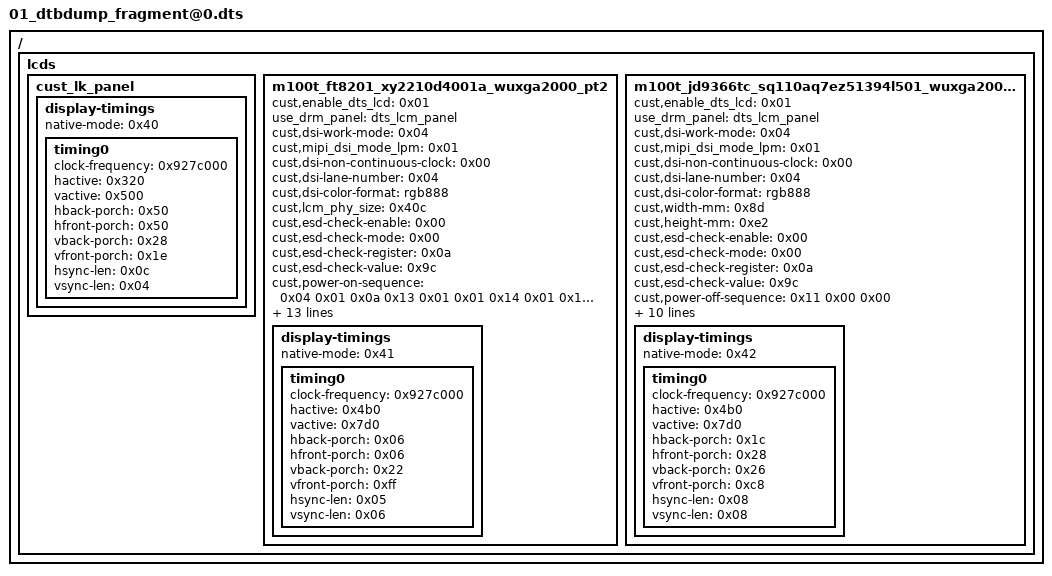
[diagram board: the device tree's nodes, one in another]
/dts-v1/;

/ {

	fragment@0 {
		target = <0xffffffff>;

		__overlay__ {

			cam0@0 {
				phandle = <0x02>;

				pins_cmd_dat {
					pinmux = <0x1400>;
					slew-rate = <0x01>;
					output-low;
				};
			};

			cam0@1 {
				phandle = <0x03>;

				pins_cmd_dat {
					pinmux = <0x1400>;
					slew-rate = <0x01>;
					output-high;
				};
			};

			cam0@2 {
				phandle = <0x17>;

				pins_cmd_dat {
					pinmux = <0x1300>;
					slew-rate = <0x01>;
					output-low;
				};
			};

			cam0@3 {
				phandle = <0x18>;

				pins_cmd_dat {
					pinmux = <0x1300>;
					slew-rate = <0x01>;
					output-high;
				};
			};

			cam1@0 {
				phandle = <0x04>;

				pins_cmd_dat {
					pinmux = <0x1000>;
					slew-rate = <0x01>;
					output-low;
				};
			};

			cam1@1 {
				phandle = <0x05>;

				pins_cmd_dat {
					pinmux = <0x1000>;
					slew-rate = <0x01>;
					output-high;
				};
			};

			cam1@2 {
				phandle = <0x19>;

				pins_cmd_dat {
					pinmux = <0x1100>;
					slew-rate = <0x01>;
					output-low;
				};
			};

			cam1@3 {
				phandle = <0x1a>;

				pins_cmd_dat {
					pinmux = <0x1100>;
					slew-rate = <0x01>;
					output-high;
				};
			};

			cam2@0 {
				phandle = <0x06>;

				pins_cmd_dat {
					pinmux = <0x1600>;
					slew-rate = <0x01>;
					output-low;
				};
			};

			cam2@1 {
				phandle = <0x07>;

				pins_cmd_dat {
					pinmux = <0x1600>;
					slew-rate = <0x01>;
					output-high;
				};
			};

			cam2@2 {
				phandle = <0x2b>;

				pins_cmd_dat {
					pinmux = <0x1500>;
					slew-rate = <0x01>;
					output-low;
				};
			};

			cam2@3 {
				phandle = <0x2c>;

				pins_cmd_dat {
					pinmux = <0x1500>;
					slew-rate = <0x01>;
					output-high;
				};
			};

			camera_pins_cam0_mclk_off {
				phandle = <0x08>;

				pins_cmd_dat {
					pinmux = <0x8000>;
					drive-strength = <0x01>;
				};
			};

			camera_pins_cam0_mclk_2ma {
				phandle = <0x09>;

				pins_cmd_dat {
					pinmux = <0x8001>;
					drive-strength = <0x00>;
				};
			};

			camera_pins_cam0_mclk_4ma {
				phandle = <0x0a>;

				pins_cmd_dat {
					pinmux = <0x8001>;
					drive-strength = <0x01>;
				};
			};

			camera_pins_cam0_mclk_6ma {
				phandle = <0x0b>;

				pins_cmd_dat {
					pinmux = <0x8001>;
					drive-strength = <0x02>;
				};
			};

			camera_pins_cam0_mclk_8ma {
				phandle = <0x0c>;

				pins_cmd_dat {
					pinmux = <0x8001>;
					drive-strength = <0x03>;
				};
			};

			camera_pins_cam1_mclk_off {
				phandle = <0x0d>;

				pins_cmd_dat {
					pinmux = <0x7e00>;
					drive-strength = <0x01>;
				};
			};

			camera_pins_cam1_mclk_2ma {
				phandle = <0x0e>;

				pins_cmd_dat {
					pinmux = <0x7e01>;
					drive-strength = <0x00>;
				};
			};

			camera_pins_cam1_mclk_4ma {
				phandle = <0x0f>;

				pins_cmd_dat {
					pinmux = <0x7e01>;
					drive-strength = <0x01>;
				};
			};

			camera_pins_cam1_mclk_6ma {
				phandle = <0x10>;

				pins_cmd_dat {
					pinmux = <0x7e01>;
					drive-strength = <0x02>;
				};
			};

			camera_pins_cam1_mclk_8ma {
				phandle = <0x11>;

				pins_cmd_dat {
					pinmux = <0x7e01>;
					drive-strength = <0x03>;
				};
			};

			camera_pins_cam2_mclk_off {
				phandle = <0x12>;

				pins_cmd_dat {
					pinmux = <0x8100>;
					drive-strength = <0x01>;
				};
			};

			camera_pins_cam2_mclk_2ma {
				phandle = <0x13>;

				pins_cmd_dat {
					pinmux = <0x8101>;
					drive-strength = <0x00>;
				};
			};

			camera_pins_cam2_mclk_4ma {
				phandle = <0x14>;

				pins_cmd_dat {
					pinmux = <0x8101>;
					drive-strength = <0x01>;
				};
			};

			camera_pins_cam2_mclk_6ma {
				phandle = <0x15>;

				pins_cmd_dat {
					pinmux = <0x8101>;
					drive-strength = <0x02>;
				};
			};

			camera_pins_cam2_mclk_8ma {
				phandle = <0x16>;

				pins_cmd_dat {
					pinmux = <0x8101>;
					drive-strength = <0x03>;
				};
			};

			camdefault {
				phandle = <0x01>;
			};

			vcama@0 {
				phandle = <0x1b>;

				pins_cmd_dat {
					pinmux = <0x9d00>;
					slew-rate = <0x01>;
					output-low;
				};
			};

			vcama@1 {
				phandle = <0x1c>;

				pins_cmd_dat {
					pinmux = <0x9d00>;
					slew-rate = <0x01>;
					output-high;
				};
			};

			vcamio@0 {
				phandle = <0x1d>;

				pins_cmd_dat {
					pinmux = <0x9f00>;
					slew-rate = <0x01>;
					output-low;
				};
			};

			vcamio@1 {
				phandle = <0x1e>;

				pins_cmd_dat {
					pinmux = <0x9f00>;
					slew-rate = <0x01>;
					output-high;
				};
			};

			vcamd@0 {
				phandle = <0x1f>;

				pins_cmd_dat {
					pinmux = <0x9e00>;
					slew-rate = <0x01>;
					output-low;
				};
			};

			vcamd@1 {
				phandle = <0x20>;

				pins_cmd_dat {
					pinmux = <0x9e00>;
					slew-rate = <0x01>;
					output-high;
				};
			};

			vcamaf@0 {
				phandle = <0x21>;

				pins_cmd_dat {
					pinmux = <0x9c00>;
					slew-rate = <0x01>;
					output-low;
				};
			};

			vcamaf@1 {
				phandle = <0x22>;

				pins_cmd_dat {
					pinmux = <0x9c00>;
					slew-rate = <0x01>;
					output-high;
				};
			};

			vcama_1@0 {
				phandle = <0x23>;

				pins_cmd_dat {
					pinmux = <0x9d00>;
					slew-rate = <0x01>;
					output-low;
				};
			};

			vcama_1@1 {
				phandle = <0x24>;

				pins_cmd_dat {
					pinmux = <0x9d00>;
					slew-rate = <0x01>;
					output-high;
				};
			};

			vcamio_1@0 {
				phandle = <0x25>;

				pins_cmd_dat {
					pinmux = <0x9f00>;
					slew-rate = <0x01>;
					output-low;
				};
			};

			vcamio_1@1 {
				phandle = <0x26>;

				pins_cmd_dat {
					pinmux = <0x9f00>;
					slew-rate = <0x01>;
					output-high;
				};
			};

			vcamd_1@0 {
				phandle = <0x27>;

				pins_cmd_dat {
					pinmux = <0x9e00>;
					slew-rate = <0x01>;
					output-low;
				};
			};

			vcamd_1@1 {
				phandle = <0x28>;

				pins_cmd_dat {
					pinmux = <0x9e00>;
					slew-rate = <0x01>;
					output-high;
				};
			};

			vcamaf_1@0 {
				phandle = <0x29>;

				pins_cmd_dat {
					pinmux = <0x9c00>;
					slew-rate = <0x01>;
					output-low;
				};
			};

			vcamaf_1@1 {
				phandle = <0x2a>;

				pins_cmd_dat {
					pinmux = <0x9c00>;
					slew-rate = <0x01>;
					output-high;
				};
			};

			vcama_2@0 {
				phandle = <0x2d>;

				pins_cmd_dat {
					pinmux = <0x9600>;
					slew-rate = <0x01>;
					output-low;
				};
			};

			vcama_2@1 {
				phandle = <0x2e>;

				pins_cmd_dat {
					pinmux = <0x9600>;
					slew-rate = <0x01>;
					output-high;
				};
			};

			vcamio_2@0 {
				phandle = <0x2f>;

				pins_cmd_dat {
					pinmux = <0x9f00>;
					slew-rate = <0x01>;
					output-low;
				};
			};

			vcamio_2@1 {
				phandle = <0x30>;

				pins_cmd_dat {
					pinmux = <0x9f00>;
					slew-rate = <0x01>;
					output-high;
				};
			};

			vcamd_2@0 {
				phandle = <0x31>;

				pins_cmd_dat {
					pinmux = <0x9700>;
					slew-rate = <0x01>;
					output-low;
				};
			};

			vcamd_2@1 {
				phandle = <0x32>;

				pins_cmd_dat {
					pinmux = <0x9700>;
					slew-rate = <0x01>;
					output-high;
				};
			};

			vcamaf_2@0 {
				phandle = <0x33>;

				pins_cmd_dat {
					pinmux = <0x9900>;
					slew-rate = <0x01>;
					output-low;
				};
			};

			vcamaf_2@1 {
				phandle = <0x34>;

				pins_cmd_dat {
					pinmux = <0x9900>;
					slew-rate = <0x01>;
					output-high;
				};
			};
		};
	};

	fragment@1 {
		target = <0xffffffff>;

		__overlay__ {
			pinctrl-names = "default\0cam0_rst0\0cam0_rst1\0cam1_rst0\0cam1_rst1\0cam2_rst0\0cam2_rst1\0cam0_mclk_off\0cam0_mclk_2mA\0cam0_mclk_4mA\0cam0_mclk_6mA\0cam0_mclk_8mA\0cam1_mclk_off\0cam1_mclk_2mA\0cam1_mclk_4mA\0cam1_mclk_6mA\0cam1_mclk_8mA\0cam2_mclk_off\0cam2_mclk_2mA\0cam2_mclk_4mA\0cam2_mclk_6mA\0cam2_mclk_8mA\0cam0_pnd0\0cam0_pnd1\0cam1_pnd0\0cam1_pnd1\0cam0_ldo_vcama_0\0cam0_ldo_vcama_1\0cam0_ldo_vcamio_0\0cam0_ldo_vcamio_1\0cam0_ldo_vcamd_0\0cam0_ldo_vcamd_1\0cam0_ldo_vcamafvdd_0\0cam0_ldo_vcamafvdd_1\0cam1_ldo_vcama_0\0cam1_ldo_vcama_1\0cam1_ldo_vcamio_0\0cam1_ldo_vcamio_1\0cam1_ldo_vcamd_0\0cam1_ldo_vcamd_1\0cam1_ldo_vcamafvdd_0\0cam1_ldo_vcamafvdd_1\0cam2_pnd0\0cam2_pnd1\0cam2_ldo_vcama_0\0cam2_ldo_vcama_1\0cam2_ldo_vcamio_0\0cam2_ldo_vcamio_1\0cam2_ldo_vcamd_0\0cam2_ldo_vcamd_1\0cam2_ldo_vcamafvdd_0\0cam2_ldo_vcamafvdd_1";
			pinctrl-0 = <0x01>;
			pinctrl-1 = <0x02>;
			pinctrl-2 = <0x03>;
			pinctrl-3 = <0x04>;
			pinctrl-4 = <0x05>;
			pinctrl-5 = <0x06>;
			pinctrl-6 = <0x07>;
			pinctrl-7 = <0x08>;
			pinctrl-8 = <0x09>;
			pinctrl-9 = <0x0a>;
			pinctrl-10 = <0x0b>;
			pinctrl-11 = <0x0c>;
			pinctrl-12 = <0x0d>;
			pinctrl-13 = <0x0e>;
			pinctrl-14 = <0x0f>;
			pinctrl-15 = <0x10>;
			pinctrl-16 = <0x11>;
			pinctrl-17 = <0x12>;
			pinctrl-18 = <0x13>;
			pinctrl-19 = <0x14>;
			pinctrl-20 = <0x15>;
			pinctrl-21 = <0x16>;
			pinctrl-22 = <0x17>;
			pinctrl-23 = <0x18>;
			pinctrl-24 = <0x19>;
			pinctrl-25 = <0x1a>;
			pinctrl-26 = <0x1b>;
			pinctrl-27 = <0x1c>;
			pinctrl-28 = <0x1d>;
			pinctrl-29 = <0x1e>;
			pinctrl-30 = <0x1f>;
			pinctrl-31 = <0x20>;
			pinctrl-32 = <0x21>;
			pinctrl-33 = <0x22>;
			pinctrl-34 = <0x23>;
			pinctrl-35 = <0x24>;
			pinctrl-36 = <0x25>;
			pinctrl-37 = <0x26>;
			pinctrl-38 = <0x27>;
			pinctrl-39 = <0x28>;
			pinctrl-40 = <0x29>;
			pinctrl-41 = <0x2a>;
			pinctrl-42 = <0x2b>;
			pinctrl-43 = <0x2c>;
			pinctrl-44 = <0x2d>;
			pinctrl-45 = <0x2e>;
			pinctrl-46 = <0x2f>;
			pinctrl-47 = <0x30>;
			pinctrl-48 = <0x31>;
			pinctrl-49 = <0x32>;
			pinctrl-50 = <0x33>;
			pinctrl-51 = <0x34>;
			cam0_pin_mclk = "mclk";
			cam0_pin_pdn = "gpio";
			cam0_pin_rst = "gpio";
			cam0_pin_vcama = "gpio";
			cam0_pin_vcamio = "gpio";
			cam0_pin_vcamd = "gpio";
			cam0_pin_vcama1 = "gpio";
			cam0_pin_vcamaf = "gpio";
			cam1_pin_mclk = "mclk";
			cam1_pin_pdn = "gpio";
			cam1_pin_rst = "gpio";
			cam1_pin_vcama = "gpio";
			cam1_pin_vcamio = "gpio";
			cam1_pin_vcamd = "gpio";
			cam1_pin_vcama1 = "gpio";
			cam1_pin_vcamaf = "gpio";
			cam2_pin_mclk = "mclk";
			cam2_pin_pdn = "gpio";
			cam2_pin_rst = "gpio";
			cam2_pin_vcama = "gpio";
			cam2_pin_vcamio = "gpio";
			cam2_pin_vcamd = "gpio";
			cam2_pin_vcama1 = "gpio";
			cam2_pin_vcamaf = "gpio";
			status = "okay";
		};
	};

	fragment@2 {
		target = <0xffffffff>;

		__overlay__ {
			status = "okay";
			clock-frequency = <0x61a80>;
			#address-cells = <0x01>;
			#size-cells = <0x00>;

			camera_eeprom2@51 {
				compatible = "mediatek,camera_eeprom";
				reg = <0x51>;
				status = "okay";
				phandle = <0x60>;
			};

			camera_main_two@10 {
				compatible = "mediatek,camera_main_two";
				#thermal-sensor-cells = <0x00>;
				reg = <0x10>;
				status = "okay";
				phandle = <0x37>;
			};

			camera_main_two_af@0d {
				compatible = "mediatek,camera_main_two_af";
				reg = <0x0d>;
				status = "okay";
				phandle = <0x61>;
			};

			camera_main_three_af@0c {
				compatible = "mediatek,camera_main_three_af";
				reg = <0x0c>;
				status = "okay";
				phandle = <0x62>;
			};
		};
	};

	fragment@3 {
		target = <0xffffffff>;

		__overlay__ {
			status = "okay";
			clock-frequency = <0x61a80>;
			#address-cells = <0x01>;
			#size-cells = <0x00>;

			camera_eeprom1@51 {
				compatible = "mediatek,camera_eeprom";
				reg = <0x51>;
				status = "okay";
				phandle = <0x63>;
			};

			camera_sub@1a {
				compatible = "mediatek,camera_sub";
				#thermal-sensor-cells = <0x00>;
				reg = <0x1a>;
				status = "okay";
				phandle = <0x36>;
			};
		};
	};

	fragment@4 {
		target = <0xffffffff>;

		__overlay__ {
			status = "okay";
			clock-frequency = <0x61a80>;
			#address-cells = <0x01>;
			#size-cells = <0x00>;

			camera_eeprom0@50 {
				compatible = "mediatek,camera_eeprom";
				reg = <0x50>;
				status = "okay";
				phandle = <0x64>;
			};

			camera_main@1a {
				compatible = "mediatek,camera_main";
				#thermal-sensor-cells = <0x00>;
				reg = <0x1a>;
				status = "okay";
				phandle = <0x35>;
			};

			camera_main_af@72 {
				compatible = "mediatek,camera_main_af";
				reg = <0x72>;
				status = "okay";
				phandle = <0x65>;
			};
		};
	};

	fragment@5 {
		target = <0xffffffff>;

		__overlay__ {

			camera_main {
				polling-delay = <0x3e8>;
				polling-delay-passive = <0x00>;
				thermal-sensors = <0x35>;
				phandle = <0x66>;
			};

			camera_sub {
				polling-delay = <0x3e8>;
				polling-delay-passive = <0x00>;
				thermal-sensors = <0x36>;
				phandle = <0x67>;
			};

			camera_main_two {
				polling-delay = <0x3e8>;
				polling-delay-passive = <0x00>;
				thermal-sensors = <0x37>;
				phandle = <0x68>;
			};
		};
	};

	fragment@6 {
		target = <0xffffffff>;

		__overlay__ {

			lm3643@63 {
				compatible = "mediatek,lm3643";
				reg = <0x63>;
				#cooling-cells = <0x02>;
				status = "okay";
				phandle = <0x69>;

				flash@0 {
					reg = <0x00>;
					type = <0x00>;
					ct = <0x00>;
					part = <0x00>;

					port@0 {

						endpoint {
							remote-endpoint = <0x38>;
							phandle = <0x3a>;
						};
					};
				};

				flash@1 {
					reg = <0x01>;
					type = <0x00>;
					ct = <0x01>;
					part = <0x00>;

					port@1 {

						endpoint {
							remote-endpoint = <0x39>;
							phandle = <0x3b>;
						};
					};
				};
			};
		};
	};

	fragment@7 {
		target = <0xffffffff>;

		__overlay__ {

			port@0 {

				endpoint {
					remote-endpoint = <0x3a>;
					phandle = <0x38>;
				};
			};

			port@1 {

				endpoint {
					remote-endpoint = <0x3b>;
					phandle = <0x39>;
				};
			};
		};
	};

	fragment@8 {
		target = <0xffffffff>;

		__overlay__ {
			camaf_m1_pmic-supply = <0xffffffff>;
			camaf_m2_pmic-supply = <0xffffffff>;
			camaf_m3_pmic-supply = <0xffffffff>;
			status = "okay";
		};
	};

	fragment@9 {
		target = <0xffffffff>;

		__overlay__ {

			hwen_high {
				phandle = <0x3c>;

				pins_cmd_dat {
					pinmux = <0x9a00>;
					slew-rate = <0x01>;
					output-high;
				};
			};

			hwen_low {
				phandle = <0x3d>;

				pins_cmd_dat {
					pinmux = <0x9a00>;
					slew-rate = <0x01>;
					output-low;
				};
			};

			mode_high {
				phandle = <0x3e>;

				pins_cmd_dat {
					pinmux = <0x9b00>;
					slew-rate = <0x01>;
					output-high;
				};
			};

			mode_low {
				phandle = <0x3f>;

				pins_cmd_dat {
					pinmux = <0x9b00>;
					slew-rate = <0x01>;
					output-low;
				};
			};
		};
	};

	fragment@10 {
		target = <0xffffffff>;

		__overlay__ {
			pinctrl-names = "hwen_high\0hwen_low\0mode_high\0mode_low";
			pinctrl-0 = <0x3c>;
			pinctrl-1 = <0x3d>;
			pinctrl-2 = <0x3e>;
			pinctrl-3 = <0x3f>;
			status = "okay";
		};
	};

	fragment@11 {
		target = <0xffffffff>;

		__overlay__ {
			DIFFERENCE_FULLOCV_ITH = <0xc8>;
			SHUTDOWN_1_TIME = <0x05>;
			KEEP_100_PERCENT = <0x01>;
			R_FG_VALUE = <0x05>;
			EMBEDDED_SEL = <0x01>;
			PMIC_SHUTDOWN_CURRENT = <0x14>;
			FG_METER_RESISTANCE = <0x46>;
			CAR_TUNE_VALUE = <0x64>;
			PMIC_MIN_VOL = <0x82dc>;
			POWERON_SYSTEM_IBOOT = <0x1f4>;
			SHUTDOWN_GAUGE0_VOLTAGE = <0x84d0>;
			TEMPERATURE_T0 = <0x32>;
			TEMPERATURE_T1 = <0x19>;
			TEMPERATURE_T2 = <0x0a>;
			TEMPERATURE_T3 = <0x00>;
			TEMPERATURE_T4 = <0xfffffff9>;
			TEMPERATURE_T5 = <0xfffffff6>;
			g_FG_PSEUDO100_T0 = <0x62>;
			g_FG_PSEUDO100_T1 = <0x62>;
			g_FG_PSEUDO100_T2 = <0x62>;
			g_FG_PSEUDO100_T3 = <0x62>;
			g_FG_PSEUDO100_T4 = <0x62>;
			Q_MAX_SYS_VOLTAGE_BAT0 = <0xd48>;
			Q_MAX_SYS_VOLTAGE_BAT1 = <0xd48>;
			Q_MAX_SYS_VOLTAGE_BAT2 = <0xd48>;
			Q_MAX_SYS_VOLTAGE_BAT3 = <0xd48>;
			COM_FG_METER_RESISTANCE = <0x64>;
			COM_R_FG_VALUE = <0x00>;
			enable_tmp_intr_suspend = <0x00>;
			ACTIVE_TABLE = <0x06>;
			MULTI_TEMP_GAUGE0 = <0x01>;
			RBAT_PULL_UP_VOLT = <0xaf0>;
			g_SHUTDOWN_HL_ZCV = <0xd48 0xd48 0xd48 0xd48 0xd48 0xd48 0xd48 0xd48 0xd48 0xd48 0xd48 0xd48 0xd48 0xd48 0xd48 0xd48 0xd48 0xd48 0xd48 0xd48>;
			UI_LOW_LIMIT_EN = <0x01>;
			UI_LOW_LIMIT_SOC0 = <0x64>;
			UI_LOW_LIMIT_VTH0 = <0x86c4>;
			UI_LOW_LIMIT_SOC1 = <0x64>;
			UI_LOW_LIMIT_VTH1 = <0x86c4>;
			UI_LOW_LIMIT_SOC2 = <0x64>;
			UI_LOW_LIMIT_VTH2 = <0x86c4>;
			UI_LOW_LIMIT_SOC3 = <0xc8>;
			UI_LOW_LIMIT_VTH3 = <0x8854>;
			UI_LOW_LIMIT_SOC4 = <0xc8>;
			UI_LOW_LIMIT_VTH4 = <0x8854>;
			VBAT2_DET_VOLTAGE1 = <0x84d0>;
			VBAT2_DET_VOLTAGE2 = <0x82dc>;
			VBAT2_DET_VOLTAGE3 = <0x80e8>;
			battery0_profile_t0_num = <0x64>;
			battery0_profile_t0_col = <0x03>;
			battery0_profile_t0 = <0x00 0xa97e 0x384 0x708 0xa776 0x384 0xa8c 0xa6fe 0x384 0xe10 0xa69a 0x384 0x1194 0xa62c 0x384 0x1518 0xa5c8 0x384 0x189c 0xa55a 0x37a 0x1c20 0xa50a 0x384 0x1fa4 0xa49c 0x384 0x26ac 0xa3e8 0x384 0x2a30 0xa384 0x384 0x2db4 0xa320 0x384 0x3138 0xa2c6 0x384 0x34bc 0xa24e 0x370 0x3840 0xa208 0x384 0x3bc4 0xa1ae 0x384 0x3f48 0xa14a 0x384 0x4650 0xa096 0x384 0x49d4 0xa03c 0x384 0x4d58 0x9fe2 0x384 0x50dc 0x9f88 0x384 0x5460 0x9f2e 0x384 0x57e4 0x9ed4 0x384 0x5b68 0x9e7a 0x384 0x5eec 0x9e2a 0x384 0x6270 0x9dda 0x384 0x6978 0x9d30 0x37a 0x6cfc 0x9cd6 0x370 0x7080 0x9c7c 0x37a 0x7404 0x9c18 0x384 0x7788 0x9ba0 0x370 0x7b0c 0x9b50 0x370 0x7e90 0x9b00 0x370 0x8214 0x9aba 0x370 0x891c 0x9a42 0x37a 0x8ca0 0x99f2 0x370 0x9024 0x99b6 0x37a 0x93a8 0x9966 0x370 0x972c 0x992a 0x37a 0x9ab0 0x98d0 0x370 0x9e34 0x9894 0x384 0xa1b8 0x984e 0x384 0xa8c0 0x97ae 0x37a 0xac44 0x9768 0x384 0xafc8 0x9722 0x384 0xb34c 0x96e6 0x384 0xb6d0 0x9696 0x370 0xba54 0x966e 0x384 0xbdd8 0x9632 0x384 0xc15c 0x9600 0x37a 0xc4e0 0x95ce 0x37a 0xcbe8 0x9574 0x384 0xcf6c 0x954c 0x384 0xd2f0 0x951a 0x37a 0xd674 0x94f2 0x384 0xd9f8 0x94ca 0x37a 0xdd7c 0x94ac 0x384 0xe100 0x9484 0x384 0xe484 0x945c 0x37a 0xeb8c 0x9416 0x37a 0xef10 0x93f8 0x384 0xf294 0x93c6 0x370 0xf618 0x93b2 0x37a 0xf99c 0x939e 0x384 0xfd20 0x9380 0x384 0x100a4 0x934e 0x370 0x10428 0x9330 0x370 0x10b30 0x9308 0x37a 0x10eb4 0x92e0 0x370 0x11238 0x92d6 0x37a 0x115bc 0x92c2 0x384 0x11940 0x92a4 0x37a 0x11cc4 0x9290 0x384 0x12048 0x927c 0x384 0x123cc 0x9268 0x384 0x12e58 0x9218 0x384 0x131dc 0x91fa 0x384 0x13560 0x91dc 0x384 0x138e4 0x91be 0x384 0x13c68 0x9196 0x384 0x13fec 0x9178 0x384 0x14370 0x915a 0x384 0x146f4 0x9128 0x384 0x14dfc 0x90c4 0x37a 0x15180 0x90a6 0x384 0x15504 0x906a 0x37a 0x15888 0x9042 0x384 0x15c0c 0x8ffc 0x384 0x15f90 0x8fca 0x384 0x16314 0x8f8e 0x37a 0x16698 0x8f7a 0x384 0x16da0 0x8f0c 0x370 0x17124 0x8ef8 0x384 0x174a8 0x8ed0 0x384 0x1782c 0x8e80 0x37a 0x17bb0 0x8e26 0x384 0x17f34 0x8db8 0x38e 0x182b8 0x8cf0 0x384 0x1863c 0x8bce 0x384 0x189c0 0x8a34 0x38e>;
			battery0_profile_t1_num = <0x64>;
			battery0_profile_t1_col = <0x03>;
			battery0_profile_t1 = <0x00 0xa97e 0x384 0x708 0xa776 0x384 0xa8c 0xa6fe 0x384 0xe10 0xa69a 0x384 0x1194 0xa62c 0x384 0x1518 0xa5c8 0x384 0x189c 0xa55a 0x37a 0x1c20 0xa50a 0x384 0x1fa4 0xa49c 0x384 0x26ac 0xa3e8 0x384 0x2a30 0xa384 0x384 0x2db4 0xa320 0x384 0x3138 0xa2c6 0x384 0x34bc 0xa24e 0x370 0x3840 0xa208 0x384 0x3bc4 0xa1ae 0x384 0x3f48 0xa14a 0x384 0x4650 0xa096 0x384 0x49d4 0xa03c 0x384 0x4d58 0x9fe2 0x384 0x50dc 0x9f88 0x384 0x5460 0x9f2e 0x384 0x57e4 0x9ed4 0x384 0x5b68 0x9e7a 0x384 0x5eec 0x9e2a 0x384 0x6270 0x9dda 0x384 0x6978 0x9d30 0x37a 0x6cfc 0x9cd6 0x370 0x7080 0x9c7c 0x37a 0x7404 0x9c18 0x384 0x7788 0x9ba0 0x370 0x7b0c 0x9b50 0x370 0x7e90 0x9b00 0x370 0x8214 0x9aba 0x370 0x891c 0x9a42 0x37a 0x8ca0 0x99f2 0x370 0x9024 0x99b6 0x37a 0x93a8 0x9966 0x370 0x972c 0x992a 0x37a 0x9ab0 0x98d0 0x370 0x9e34 0x9894 0x384 0xa1b8 0x984e 0x384 0xa8c0 0x97ae 0x37a 0xac44 0x9768 0x384 0xafc8 0x9722 0x384 0xb34c 0x96e6 0x384 0xb6d0 0x9696 0x370 0xba54 0x966e 0x384 0xbdd8 0x9632 0x384 0xc15c 0x9600 0x37a 0xc4e0 0x95ce 0x37a 0xcbe8 0x9574 0x384 0xcf6c 0x954c 0x384 0xd2f0 0x951a 0x37a 0xd674 0x94f2 0x384 0xd9f8 0x94ca 0x37a 0xdd7c 0x94ac 0x384 0xe100 0x9484 0x384 0xe484 0x945c 0x37a 0xeb8c 0x9416 0x37a 0xef10 0x93f8 0x384 0xf294 0x93c6 0x370 0xf618 0x93b2 0x37a 0xf99c 0x939e 0x384 0xfd20 0x9380 0x384 0x100a4 0x934e 0x370 0x10428 0x9330 0x370 0x10b30 0x9308 0x37a 0x10eb4 0x92e0 0x370 0x11238 0x92d6 0x37a 0x115bc 0x92c2 0x384 0x11940 0x92a4 0x37a 0x11cc4 0x9290 0x384 0x12048 0x927c 0x384 0x123cc 0x9268 0x384 0x12e58 0x9218 0x384 0x131dc 0x91fa 0x384 0x13560 0x91dc 0x384 0x138e4 0x91be 0x384 0x13c68 0x9196 0x384 0x13fec 0x9178 0x384 0x14370 0x915a 0x384 0x146f4 0x9128 0x384 0x14dfc 0x90c4 0x37a 0x15180 0x90a6 0x384 0x15504 0x906a 0x37a 0x15888 0x9042 0x384 0x15c0c 0x8ffc 0x384 0x15f90 0x8fca 0x384 0x16314 0x8f8e 0x37a 0x16698 0x8f7a 0x384 0x16da0 0x8f0c 0x370 0x17124 0x8ef8 0x384 0x174a8 0x8ed0 0x384 0x1782c 0x8e80 0x37a 0x17bb0 0x8e26 0x384 0x17f34 0x8db8 0x38e 0x182b8 0x8cf0 0x384 0x1863c 0x8bce 0x384 0x189c0 0x8a34 0x38e>;
			battery0_profile_t2_num = <0x64>;
			battery0_profile_t2_col = <0x03>;
			battery0_profile_t2 = <0x00 0xa97e 0x384 0x708 0xa776 0x384 0xa8c 0xa6fe 0x384 0xe10 0xa69a 0x384 0x1194 0xa62c 0x384 0x1518 0xa5c8 0x384 0x189c 0xa55a 0x37a 0x1c20 0xa50a 0x384 0x1fa4 0xa49c 0x384 0x26ac 0xa3e8 0x384 0x2a30 0xa384 0x384 0x2db4 0xa320 0x384 0x3138 0xa2c6 0x384 0x34bc 0xa24e 0x370 0x3840 0xa208 0x384 0x3bc4 0xa1ae 0x384 0x3f48 0xa14a 0x384 0x4650 0xa096 0x384 0x49d4 0xa03c 0x384 0x4d58 0x9fe2 0x384 0x50dc 0x9f88 0x384 0x5460 0x9f2e 0x384 0x57e4 0x9ed4 0x384 0x5b68 0x9e7a 0x384 0x5eec 0x9e2a 0x384 0x6270 0x9dda 0x384 0x6978 0x9d30 0x37a 0x6cfc 0x9cd6 0x370 0x7080 0x9c7c 0x37a 0x7404 0x9c18 0x384 0x7788 0x9ba0 0x370 0x7b0c 0x9b50 0x370 0x7e90 0x9b00 0x370 0x8214 0x9aba 0x370 0x891c 0x9a42 0x37a 0x8ca0 0x99f2 0x370 0x9024 0x99b6 0x37a 0x93a8 0x9966 0x370 0x972c 0x992a 0x37a 0x9ab0 0x98d0 0x370 0x9e34 0x9894 0x384 0xa1b8 0x984e 0x384 0xa8c0 0x97ae 0x37a 0xac44 0x9768 0x384 0xafc8 0x9722 0x384 0xb34c 0x96e6 0x384 0xb6d0 0x9696 0x370 0xba54 0x966e 0x384 0xbdd8 0x9632 0x384 0xc15c 0x9600 0x37a 0xc4e0 0x95ce 0x37a 0xcbe8 0x9574 0x384 0xcf6c 0x954c 0x384 0xd2f0 0x951a 0x37a 0xd674 0x94f2 0x384 0xd9f8 0x94ca 0x37a 0xdd7c 0x94ac 0x384 0xe100 0x9484 0x384 0xe484 0x945c 0x37a 0xeb8c 0x9416 0x37a 0xef10 0x93f8 0x384 0xf294 0x93c6 0x370 0xf618 0x93b2 0x37a 0xf99c 0x939e 0x384 0xfd20 0x9380 0x384 0x100a4 0x934e 0x370 0x10428 0x9330 0x370 0x10b30 0x9308 0x37a 0x10eb4 0x92e0 0x370 0x11238 0x92d6 0x37a 0x115bc 0x92c2 0x384 0x11940 0x92a4 0x37a 0x11cc4 0x9290 0x384 0x12048 0x927c 0x384 0x123cc 0x9268 0x384 0x12e58 0x9218 0x384 0x131dc 0x91fa 0x384 0x13560 0x91dc 0x384 0x138e4 0x91be 0x384 0x13c68 0x9196 0x384 0x13fec 0x9178 0x384 0x14370 0x915a 0x384 0x146f4 0x9128 0x384 0x14dfc 0x90c4 0x37a 0x15180 0x90a6 0x384 0x15504 0x906a 0x37a 0x15888 0x9042 0x384 0x15c0c 0x8ffc 0x384 0x15f90 0x8fca 0x384 0x16314 0x8f8e 0x37a 0x16698 0x8f7a 0x384 0x16da0 0x8f0c 0x370 0x17124 0x8ef8 0x384 0x174a8 0x8ed0 0x384 0x1782c 0x8e80 0x37a 0x17bb0 0x8e26 0x384 0x17f34 0x8db8 0x38e 0x182b8 0x8cf0 0x384 0x1863c 0x8bce 0x384 0x189c0 0x8a34 0x38e>;
			battery0_profile_t3_num = <0x64>;
			battery0_profile_t3_col = <0x03>;
			battery0_profile_t3 = <0x00 0xa97e 0x384 0x708 0xa776 0x384 0xa8c 0xa6fe 0x384 0xe10 0xa69a 0x384 0x1194 0xa62c 0x384 0x1518 0xa5c8 0x384 0x189c 0xa55a 0x37a 0x1c20 0xa50a 0x384 0x1fa4 0xa49c 0x384 0x26ac 0xa3e8 0x384 0x2a30 0xa384 0x384 0x2db4 0xa320 0x384 0x3138 0xa2c6 0x384 0x34bc 0xa24e 0x370 0x3840 0xa208 0x384 0x3bc4 0xa1ae 0x384 0x3f48 0xa14a 0x384 0x4650 0xa096 0x384 0x49d4 0xa03c 0x384 0x4d58 0x9fe2 0x384 0x50dc 0x9f88 0x384 0x5460 0x9f2e 0x384 0x57e4 0x9ed4 0x384 0x5b68 0x9e7a 0x384 0x5eec 0x9e2a 0x384 0x6270 0x9dda 0x384 0x6978 0x9d30 0x37a 0x6cfc 0x9cd6 0x370 0x7080 0x9c7c 0x37a 0x7404 0x9c18 0x384 0x7788 0x9ba0 0x370 0x7b0c 0x9b50 0x370 0x7e90 0x9b00 0x370 0x8214 0x9aba 0x370 0x891c 0x9a42 0x37a 0x8ca0 0x99f2 0x370 0x9024 0x99b6 0x37a 0x93a8 0x9966 0x370 0x972c 0x992a 0x37a 0x9ab0 0x98d0 0x370 0x9e34 0x9894 0x384 0xa1b8 0x984e 0x384 0xa8c0 0x97ae 0x37a 0xac44 0x9768 0x384 0xafc8 0x9722 0x384 0xb34c 0x96e6 0x384 0xb6d0 0x9696 0x370 0xba54 0x966e 0x384 0xbdd8 0x9632 0x384 0xc15c 0x9600 0x37a 0xc4e0 0x95ce 0x37a 0xcbe8 0x9574 0x384 0xcf6c 0x954c 0x384 0xd2f0 0x951a 0x37a 0xd674 0x94f2 0x384 0xd9f8 0x94ca 0x37a 0xdd7c 0x94ac 0x384 0xe100 0x9484 0x384 0xe484 0x945c 0x37a 0xeb8c 0x9416 0x37a 0xef10 0x93f8 0x384 0xf294 0x93c6 0x370 0xf618 0x93b2 0x37a 0xf99c 0x939e 0x384 0xfd20 0x9380 0x384 0x100a4 0x934e 0x370 0x10428 0x9330 0x370 0x10b30 0x9308 0x37a 0x10eb4 0x92e0 0x370 0x11238 0x92d6 0x37a 0x115bc 0x92c2 0x384 0x11940 0x92a4 0x37a 0x11cc4 0x9290 0x384 0x12048 0x927c 0x384 0x123cc 0x9268 0x384 0x12e58 0x9218 0x384 0x131dc 0x91fa 0x384 0x13560 0x91dc 0x384 0x138e4 0x91be 0x384 0x13c68 0x9196 0x384 0x13fec 0x9178 0x384 0x14370 0x915a 0x384 0x146f4 0x9128 0x384 0x14dfc 0x90c4 0x37a 0x15180 0x90a6 0x384 0x15504 0x906a 0x37a 0x15888 0x9042 0x384 0x15c0c 0x8ffc 0x384 0x15f90 0x8fca 0x384 0x16314 0x8f8e 0x37a 0x16698 0x8f7a 0x384 0x16da0 0x8f0c 0x370 0x17124 0x8ef8 0x384 0x174a8 0x8ed0 0x384 0x1782c 0x8e80 0x37a 0x17bb0 0x8e26 0x384 0x17f34 0x8db8 0x38e 0x182b8 0x8cf0 0x384 0x1863c 0x8bce 0x384 0x189c0 0x8a34 0x38e>;
			battery0_profile_t4_num = <0x64>;
			battery0_profile_t4_col = <0x03>;
			battery0_profile_t4 = <0x00 0xa97e 0x384 0x708 0xa776 0x384 0xa8c 0xa6fe 0x384 0xe10 0xa69a 0x384 0x1194 0xa62c 0x384 0x1518 0xa5c8 0x384 0x189c 0xa55a 0x37a 0x1c20 0xa50a 0x384 0x1fa4 0xa49c 0x384 0x26ac 0xa3e8 0x384 0x2a30 0xa384 0x384 0x2db4 0xa320 0x384 0x3138 0xa2c6 0x384 0x34bc 0xa24e 0x370 0x3840 0xa208 0x384 0x3bc4 0xa1ae 0x384 0x3f48 0xa14a 0x384 0x4650 0xa096 0x384 0x49d4 0xa03c 0x384 0x4d58 0x9fe2 0x384 0x50dc 0x9f88 0x384 0x5460 0x9f2e 0x384 0x57e4 0x9ed4 0x384 0x5b68 0x9e7a 0x384 0x5eec 0x9e2a 0x384 0x6270 0x9dda 0x384 0x6978 0x9d30 0x37a 0x6cfc 0x9cd6 0x370 0x7080 0x9c7c 0x37a 0x7404 0x9c18 0x384 0x7788 0x9ba0 0x370 0x7b0c 0x9b50 0x370 0x7e90 0x9b00 0x370 0x8214 0x9aba 0x370 0x891c 0x9a42 0x37a 0x8ca0 0x99f2 0x370 0x9024 0x99b6 0x37a 0x93a8 0x9966 0x370 0x972c 0x992a 0x37a 0x9ab0 0x98d0 0x370 0x9e34 0x9894 0x384 0xa1b8 0x984e 0x384 0xa8c0 0x97ae 0x37a 0xac44 0x9768 0x384 0xafc8 0x9722 0x384 0xb34c 0x96e6 0x384 0xb6d0 0x9696 0x370 0xba54 0x966e 0x384 0xbdd8 0x9632 0x384 0xc15c 0x9600 0x37a 0xc4e0 0x95ce 0x37a 0xcbe8 0x9574 0x384 0xcf6c 0x954c 0x384 0xd2f0 0x951a 0x37a 0xd674 0x94f2 0x384 0xd9f8 0x94ca 0x37a 0xdd7c 0x94ac 0x384 0xe100 0x9484 0x384 0xe484 0x945c 0x37a 0xeb8c 0x9416 0x37a 0xef10 0x93f8 0x384 0xf294 0x93c6 0x370 0xf618 0x93b2 0x37a 0xf99c 0x939e 0x384 0xfd20 0x9380 0x384 0x100a4 0x934e 0x370 0x10428 0x9330 0x370 0x10b30 0x9308 0x37a 0x10eb4 0x92e0 0x370 0x11238 0x92d6 0x37a 0x115bc 0x92c2 0x384 0x11940 0x92a4 0x37a 0x11cc4 0x9290 0x384 0x12048 0x927c 0x384 0x123cc 0x9268 0x384 0x12e58 0x9218 0x384 0x131dc 0x91fa 0x384 0x13560 0x91dc 0x384 0x138e4 0x91be 0x384 0x13c68 0x9196 0x384 0x13fec 0x9178 0x384 0x14370 0x915a 0x384 0x146f4 0x9128 0x384 0x14dfc 0x90c4 0x37a 0x15180 0x90a6 0x384 0x15504 0x906a 0x37a 0x15888 0x9042 0x384 0x15c0c 0x8ffc 0x384 0x15f90 0x8fca 0x384 0x16314 0x8f8e 0x37a 0x16698 0x8f7a 0x384 0x16da0 0x8f0c 0x370 0x17124 0x8ef8 0x384 0x174a8 0x8ed0 0x384 0x1782c 0x8e80 0x37a 0x17bb0 0x8e26 0x384 0x17f34 0x8db8 0x38e 0x182b8 0x8cf0 0x384 0x1863c 0x8bce 0x384 0x189c0 0x8a34 0x38e>;
			battery0_profile_t5_num = <0x64>;
			battery0_profile_t5_col = <0x03>;
			battery0_profile_t5 = <0x00 0xa97e 0x384 0x708 0xa776 0x384 0xa8c 0xa6fe 0x384 0xe10 0xa69a 0x384 0x1194 0xa62c 0x384 0x1518 0xa5c8 0x384 0x189c 0xa55a 0x37a 0x1c20 0xa50a 0x384 0x1fa4 0xa49c 0x384 0x26ac 0xa3e8 0x384 0x2a30 0xa384 0x384 0x2db4 0xa320 0x384 0x3138 0xa2c6 0x384 0x34bc 0xa24e 0x370 0x3840 0xa208 0x384 0x3bc4 0xa1ae 0x384 0x3f48 0xa14a 0x384 0x4650 0xa096 0x384 0x49d4 0xa03c 0x384 0x4d58 0x9fe2 0x384 0x50dc 0x9f88 0x384 0x5460 0x9f2e 0x384 0x57e4 0x9ed4 0x384 0x5b68 0x9e7a 0x384 0x5eec 0x9e2a 0x384 0x6270 0x9dda 0x384 0x6978 0x9d30 0x37a 0x6cfc 0x9cd6 0x370 0x7080 0x9c7c 0x37a 0x7404 0x9c18 0x384 0x7788 0x9ba0 0x370 0x7b0c 0x9b50 0x370 0x7e90 0x9b00 0x370 0x8214 0x9aba 0x370 0x891c 0x9a42 0x37a 0x8ca0 0x99f2 0x370 0x9024 0x99b6 0x37a 0x93a8 0x9966 0x370 0x972c 0x992a 0x37a 0x9ab0 0x98d0 0x370 0x9e34 0x9894 0x384 0xa1b8 0x984e 0x384 0xa8c0 0x97ae 0x37a 0xac44 0x9768 0x384 0xafc8 0x9722 0x384 0xb34c 0x96e6 0x384 0xb6d0 0x9696 0x370 0xba54 0x966e 0x384 0xbdd8 0x9632 0x384 0xc15c 0x9600 0x37a 0xc4e0 0x95ce 0x37a 0xcbe8 0x9574 0x384 0xcf6c 0x954c 0x384 0xd2f0 0x951a 0x37a 0xd674 0x94f2 0x384 0xd9f8 0x94ca 0x37a 0xdd7c 0x94ac 0x384 0xe100 0x9484 0x384 0xe484 0x945c 0x37a 0xeb8c 0x9416 0x37a 0xef10 0x93f8 0x384 0xf294 0x93c6 0x370 0xf618 0x93b2 0x37a 0xf99c 0x939e 0x384 0xfd20 0x9380 0x384 0x100a4 0x934e 0x370 0x10428 0x9330 0x370 0x10b30 0x9308 0x37a 0x10eb4 0x92e0 0x370 0x11238 0x92d6 0x37a 0x115bc 0x92c2 0x384 0x11940 0x92a4 0x37a 0x11cc4 0x9290 0x384 0x12048 0x927c 0x384 0x123cc 0x9268 0x384 0x12e58 0x9218 0x384 0x131dc 0x91fa 0x384 0x13560 0x91dc 0x384 0x138e4 0x91be 0x384 0x13c68 0x9196 0x384 0x13fec 0x9178 0x384 0x14370 0x915a 0x384 0x146f4 0x9128 0x384 0x14dfc 0x90c4 0x37a 0x15180 0x90a6 0x384 0x15504 0x906a 0x37a 0x15888 0x9042 0x384 0x15c0c 0x8ffc 0x384 0x15f90 0x8fca 0x384 0x16314 0x8f8e 0x37a 0x16698 0x8f7a 0x384 0x16da0 0x8f0c 0x370 0x17124 0x8ef8 0x384 0x174a8 0x8ed0 0x384 0x1782c 0x8e80 0x37a 0x17bb0 0x8e26 0x384 0x17f34 0x8db8 0x38e 0x182b8 0x8cf0 0x384 0x1863c 0x8bce 0x384 0x189c0 0x8a34 0x38e>;
			g_PMIC_MIN_VOL_row = <0x04>;
			g_PMIC_MIN_VOL_col = <0x0a>;
			g_PMIC_MIN_VOL = <0x82dc 0x82dc 0x82dc 0x82dc 0x80e8 0x80e8 0x80e8 0x80e8 0x80e8 0x80e8 0x80e8 0x80e8 0x7dc8 0x7dc8 0x7dc8 0x7dc8 0x7918 0x7918 0x7918 0x7918 0x7b0c 0x7b0c 0x7b0c 0x7b0c 0x7918 0x7918 0x7918 0x7918 0x7918 0x7918 0x7918 0x7918 0x7918 0x7918 0x7918 0x7918 0x7918 0x7918 0x7918 0x79e0>;
			g_PON_SYS_IBOOT_row = <0x04>;
			g_PON_SYS_IBOOT_col = <0x0a>;
			g_PON_SYS_IBOOT = <0x1388 0x1388 0x1388 0x1388 0x1388 0x1388 0x1388 0x1388 0x1388 0x1388 0x1388 0x1388 0x1388 0x1388 0x1388 0x1388 0x1388 0x1388 0x1388 0x1388 0x1388 0x1388 0x1388 0x1388 0x1388 0x1388 0x1388 0x1388 0x1388 0x1388 0x1388 0x1388 0x1388 0x1388 0x1388 0x1388 0x1388 0x1388 0x1388 0x1388>;
			g_QMAX_SYS_VOL_row = <0x04>;
			g_QMAX_SYS_VOL_col = <0x0a>;
			g_QMAX_SYS_VOL = <0x16760 0x16760 0x16760 0x16760 0x16760 0x16760 0x16760 0x16760 0x1656c 0x1656c 0x1656c 0x1656c 0x1656c 0x1656c 0x1656c 0x1656c 0x1656c 0x1656c 0x1656c 0x1656c 0x16378 0x16378 0x16378 0x16378 0x164a4 0x164a4 0x164a4 0x164a4 0x164a4 0x164a4 0x164a4 0x164a4 0x164a4 0x164a4 0x164a4 0x164a4 0x164a4 0x164a4 0x164a4 0x164a4>;
			g_FG_PSEUDO100_row = <0x04>;
			g_FG_PSEUDO100_col = <0x0a>;
			g_FG_PSEUDO100 = <0x62 0x62 0x62 0x62 0x62 0x62 0x62 0x62 0x62 0x62 0x62 0x62 0x62 0x62 0x62 0x62 0x62 0x62 0x62 0x62 0x62 0x62 0x62 0x62 0x62 0x62 0x62 0x62 0x62 0x62 0x62 0x62 0x62 0x62 0x62 0x62 0x62 0x62 0x62 0x62>;
			g_FG_charge_PSEUDO100_row = <0x04>;
			g_FG_charge_PSEUDO100_col = <0x0a>;
			g_FG_charge_PSEUDO100 = <0x62 0x62 0x62 0x62 0x62 0x62 0x62 0x62 0x62 0x62 0x62 0x62 0x62 0x62 0x62 0x62 0x62 0x62 0x62 0x62 0x62 0x62 0x62 0x62 0x62 0x62 0x62 0x62 0x62 0x62 0x62 0x62 0x62 0x62 0x62 0x62 0x62 0x62 0x62 0x62>;
		};
	};

	fragment {
		target-path = "/";

		__overlay__ {

			lcds {

				cust_lk_panel {
					phandle = <0x6a>;

					display-timings {
						native-mode = <0x40>;

						timing0 {
							clock-frequency = <0x927c000>;
							hactive = <0x320>;
							vactive = <0x500>;
							hback-porch = <0x50>;
							hfront-porch = <0x50>;
							vback-porch = <0x28>;
							vfront-porch = <0x1e>;
							hsync-len = <0x0c>;
							vsync-len = <0x04>;
							phandle = <0x40>;
						};
					};
				};

				m100t_ft8201_xy2210d4001a_wuxga2000_pt2 {
					cust,enable_dts_lcd = <0x01>;
					use_drm_panel = "dts_lcm_panel";
					cust,dsi-work-mode = <0x04>;
					cust,mipi_dsi_mode_lpm = <0x01>;
					cust,dsi-non-continuous-clock = <0x00>;
					cust,dsi-lane-number = <0x04>;
					cust,dsi-color-format = "rgb888";
					cust,lcm_phy_size = <0x40c>;
					cust,esd-check-enable = <0x00>;
					cust,esd-check-mode = <0x00>;
					cust,esd-check-register = <0x0a>;
					cust,esd-check-value = <0x9c>;
					cust,power-on-sequence = <0x04 0x01 0x0a 0x13 0x01 0x01 0x14 0x01 0x14 0x11 0x00 0x01 0x11 0x01 0x01 0x05 0x01 0x0a 0x05 0x00 0x02 0x05 0x01 0x05>;
					cust,power-on-sequence_after_cmd = <0x16 0x01 0x00>;
					cust,power-off-sequence = <0x16 0x00 0x00 0x11 0x00 0x0a 0x04 0x00 0x0a 0x13 0x00 0x02 0x14 0x00 0x00>;
					cust,initial-command = [00 02 50 5a 00 02 54 03 00 03 50 5a 03 00 02 80 ee 00 03 50 5a 08 00 03 80 c8 00 00 03 50 5a 09 00 11 80 5a 51 b5 2a 6c d5 4a 01 80 e0 cd f3 3c 0f 00 b7 00 11 90 00 3f 42 0a e3 6d db f0 91 5c 62 20 6b a1 26 00 00 07 a0 01 82 08 20 06 00 00 03 50 5a 0a 00 11 80 a5 4b 03 00 1c 30 48 5f 72 7c b1 b4 ef 4a 18 6a 00 11 90 43 43 36 2a 1c 16 17 00 1c 30 48 5f 72 7c b1 b4 00 0d a0 ef 4a 18 6a 43 43 36 2a 1c 16 03 00 00 03 50 5a 0b 00 11 80 00 00 20 44 08 00 60 47 00 00 10 22 04 00 b0 23 00 03 90 15 00 00 03 50 5a 0c 00 11 80 fe 68 58 82 3e 64 b8 06 00 60 15 00 50 15 56 51 00 11 90 15 55 61 15 00 60 15 00 50 15 56 51 15 55 61 95 00 11 a0 ab 18 00 05 00 05 00 05 80 4c 29 84 52 01 09 00 00 03 50 5a 0d 00 0f 80 f0 b1 71 ef 49 c0 80 1a 00 00 00 00 00 00 00 03 50 5a 0e 00 0d 80 ff 81 68 ec 22 6d 22 00 00 00 00 00 00 03 50 5a 0f 00 11 80 0d 08 4a 00 25 80 64 0c 51 11 c8 50 01 42 8c 8c 00 08 90 24 69 81 71 44 7c 14 00 03 50 5a 10 00 11 80 00 78 03 e7 1f 17 00 78 20 d3 d4 18 30 88 41 8a 00 10 90 39 28 a9 c5 9a 7b fa 07 7e e0 07 7e 20 10 00 00 03 50 5a 11 00 11 80 46 77 03 40 ca f3 ff 83 30 08 c4 06 a1 d8 24 18 00 11 90 30 c6 66 c1 80 31 15 cb e5 d2 68 6c 36 1d 04 c8 00 11 a0 b0 d9 88 60 b0 81 40 1a 1b 48 63 03 b9 00 1c 80 00 11 b0 50 30 00 e0 e1 01 00 28 0e 06 43 55 55 55 55 55 00 11 c0 95 88 88 88 88 88 c8 08 86 c6 e3 81 00 20 00 21 00 11 d0 42 88 00 00 00 00 40 00 00 31 04 41 06 00 00 00 00 11 e0 00 00 00 00 00 00 00 00 00 00 92 04 00 85 11 0c 00 0a f0 00 00 40 00 00 00 00 5e 00 00 03 50 5a 12 00 11 80 00 00 00 00 00 00 00 00 00 00 00 00 00 00 00 00 00 0a 90 00 00 00 00 00 00 00 74 00 00 03 50 5a 13 00 11 80 01 00 00 0c 00 00 00 00 01 02 01 01 44 0c ce e7 00 04 90 62 06 00 00 03 50 5a 14 00 11 80 d1 00 40 5e e9 ef f7 fb fd 7e 01 00 00 f4 c5 41 00 11 90 88 1c 60 0e 42 e4 00 9b 10 22 07 80 8b 10 39 80 00 11 a0 39 e4 c8 08 cc 80 21 45 00 00 00 00 00 00 00 00 00 11 b0 00 00 00 00 00 00 10 00 00 ec be e8 1b 00 40 a1 00 11 c0 50 b8 01 21 72 80 31 00 37 21 44 0e 30 06 e0 46 00 11 d0 84 c8 01 c6 00 dc 8c 10 39 c0 18 80 1b 12 22 07 00 11 e0 18 03 70 53 42 e4 00 63 00 dc 04 8e 1c 60 0c 80 00 11 f0 7b c0 91 07 8c 01 18 01 bf 5f 08 00 00 00 00 00 00 03 50 5a 15 00 11 80 00 00 00 00 00 00 00 00 00 00 00 00 52 d4 e0 e7 00 11 90 f3 00 e8 63 41 c8 80 86 60 40 1d 31 32 a0 21 18 00 11 a0 50 00 00 00 00 00 00 00 00 00 00 00 00 00 00 00 00 11 b0 00 00 00 00 00 00 00 40 13 00 f0 00 94 b6 6d db 00 11 c0 b6 6d db 95 92 3e 4e 41 0c 42 00 a0 b6 6d db b6 00 11 d0 6d db b6 5d ab e8 e3 82 a1 38 92 65 6a db b6 6d 00 11 e0 db b6 6d db b5 9a 3e 6e 49 8e 62 08 a2 b6 6d db 00 11 f0 b6 6d db b6 5d 29 e8 e3 00 81 30 10 45 6a 5b 00 00 03 50 5a 16 00 11 80 00 00 00 00 00 00 00 00 00 00 00 00 00 00 00 00 00 07 90 00 00 00 00 90 40 00 03 50 5a 18 00 11 80 ef bd f7 de 7b ef bd 07 08 08 0a 0c 0c 0c 0c 0c 00 11 90 0c 0c 0c 5c 09 a8 aa aa aa aa aa aa aa aa aa 5a 00 11 a0 59 59 59 59 59 59 59 59 59 59 59 09 04 ff 05 80 00 10 b0 80 00 04 20 00 01 08 40 00 02 10 80 00 04 0f 00 03 50 5a 19 00 11 80 eb d6 b9 b3 a8 9d 98 91 8c 87 84 82 66 f6 ff ff 00 11 90 ff ff ff ff ff 7f 0f 0f af b5 71 0e 6c 4a 69 08 00 08 a0 00 04 62 00 00 00 00 00 03 50 5a 1a 00 11 80 00 04 08 0c 00 10 14 18 1c 00 20 28 30 38 00 3f 00 11 90 47 4f 57 ff 5f 67 6f 77 aa 7f 87 8f 97 aa 9f a7 00 11 a0 af b7 ff bf c7 d0 d8 0f e0 e8 f0 f8 00 fc fe ff 00 11 b0 00 00 03 07 0b bc 0f 13 17 1b 16 1f 26 2e 36 6c 00 11 c0 3e 45 4d 55 6c 5d 65 6c 74 b0 7c 84 8b 93 b1 9b 00 11 d0 a3 aa b2 61 ba c1 c9 d1 6c d9 e0 e8 f0 6c f4 f6 00 11 e0 f7 00 00 03 07 0b ac 0f 13 16 1a b1 1e 26 2d 35 00 11 f0 21 3c 44 4b 53 77 5b 62 6a 71 88 79 80 88 90 1d 00 03 50 5a 1b 00 11 80 97 9f a6 ae 72 b6 bd c5 cd 1c d4 dc e4 ec 5b f0 00 05 90 f2 f3 15 00 00 03 50 5a 20 00 08 80 90 00 00 00 00 00 00 00 03 50 5a 22 00 0e 80 2d d3 00 41 10 04 41 10 04 41 10 1e 00 00 03 50 5a 23 00 11 80 01 05 00 05 00 00 00 00 00 00 00 00 00 00 00 00 00 0a 90 ff 0f 00 00 2c 00 00 00 00 00 03 50 5a 24 00 11 80 00 03 00 9d bf 10 00 00 00 00 00 00 00 00 77 62 00 02 90 a5 00 03 50 5a 2f 00 02 09 01 78 02 11 00 0a 02 29 00];
					cust,sleep-in-command = [0a 01 28 78 01 10];
					cust,sleep-out-command = [78 01 11 64 01 29];
					cust,pll_clk = <0x223>;
					cust,data_rate = <0x434>;
					cust,rotate = <0x01>;
					cust,ssc_enable = <0x00>;
					cust,fps = <0x3c>;
					phandle = <0x6b>;

					display-timings {
						native-mode = <0x41>;

						timing0 {
							clock-frequency = <0x927c000>;
							hactive = <0x4b0>;
							vactive = <0x7d0>;
							hback-porch = <0x06>;
							hfront-porch = <0x06>;
							vback-porch = <0x22>;
							vfront-porch = <0xff>;
							hsync-len = <0x05>;
							vsync-len = <0x06>;
							phandle = <0x41>;
						};
					};
				};

				m100t_jd9366tc_sq110aq7ez51394l501_wuxga2000_jst_864 {
					cust,enable_dts_lcd = <0x01>;
					use_drm_panel = "dts_lcm_panel";
					cust,dsi-work-mode = <0x04>;
					cust,mipi_dsi_mode_lpm = <0x01>;
					cust,dsi-non-continuous-clock = <0x00>;
					cust,dsi-lane-number = <0x04>;
					cust,dsi-color-format = "rgb888";
					cust,width-mm = <0x8d>;
					cust,height-mm = <0xe2>;
					cust,esd-check-enable = <0x00>;
					cust,esd-check-mode = <0x00>;
					cust,esd-check-register = <0x0a>;
					cust,esd-check-value = <0x9c>;
					cust,power-off-sequence = <0x11 0x00 0x00>;
					cust,initial-command = [00 02 30 01 00 05 78 49 61 02 00 00 02 30 02 00 02 31 22 00 02 32 10 00 02 33 36 00 02 3d 42 00 02 3f 61 00 02 42 82 00 02 43 70 00 02 44 21 00 02 49 82 00 02 4a 3f 00 0d 41 00 00 00 00 00 00 0c 0c 00 00 00 00 00 0c 5a 23 23 23 23 23 23 23 19 23 21 20 00 0c 5b 17 15 13 11 0f 0d 0b 09 01 23 23 00 0c 5c 23 23 23 23 23 23 23 18 23 21 20 00 0c 5d 16 14 12 10 0e 0c 0a 08 00 23 23 00 03 4e ff ff 00 03 50 01 01 00 03 55 00 00 00 03 56 00 00 00 04 6f 00 04 00 00 04 70 00 04 00 00 04 71 ff ff 3f 00 04 72 ff ff 3f 00 02 30 05 00 02 31 00 00 04 40 6f 39 39 00 02 30 07 00 02 31 c0 00 02 30 02 00 02 30 08 00 02 40 3d 00 02 41 3d 00 02 42 0f 00 02 47 0a 00 02 48 0c 00 02 4a 17 00 02 4b 1a 00 02 4c a0 00 02 4e a0 00 02 50 0a 00 02 52 83 00 02 5a b0 00 02 5b d0 00 02 5c 74 00 02 62 04 00 02 65 5f 00 02 7e 0f 00 02 5e 00 00 02 73 01 00 02 30 0a 00 02 32 3f 00 02 3f 50 00 02 42 31 00 02 43 00 00 02 49 03 00 02 30 0b 00 03 33 00 54 00 03 3c 00 92 00 02 43 ab 00 02 44 2b 00 06 3e 00 00 08 0d 13 00 0f 3f 1a 30 36 3d 39 56 5e 67 7a 7c 88 95 a5 a3 00 0a 40 50 58 5f 65 00 00 08 0d 13 00 0f 41 1a 30 36 3d 39 56 5e 67 7a 7c 88 95 a5 a3 00 05 42 50 58 70 73 00 02 45 59 00 02 46 45 00 02 48 7e 00 02 49 1f 00 02 4a 1a 00 02 4e 0a 00 02 4f 96 00 02 50 50 00 02 5a 18 00 02 5b 72 00 02 60 13 00 02 61 3f 00 02 67 14 00 02 30 0c 00 02 4a ab 00 02 4b d3 00 02 32 62 00 02 42 34 00 02 5e 00 00 02 6a 7f 00 02 62 41 00 02 30 0d 00 02 4c 74 00 02 30 08 00 02 52 c3 00 02 54 20 00 02 30 08 00 02 30 00 00 02 11 00 00 02 29 00 00 02 35 00 00 02 30 0c 00 02 4a ab 00 02 4b d3 00 02 30 00];
					cust,sleep-in-command = [0a 01 28 78 01 10 00 02 30 0b 00 02 31 01 00 02 30 00];
					cust,sleep-out-command = [78 01 11 64 01 29];
					cust,pll_clk = <0x226>;
					cust,data_rate = <0x44c>;
					cust,rotate = <0x01>;
					cust,ssc_enable = <0x00>;
					cust,fps = <0x3c>;
					phandle = <0x6c>;

					display-timings {
						native-mode = <0x42>;

						timing0 {
							clock-frequency = <0x927c000>;
							hactive = <0x4b0>;
							vactive = <0x7d0>;
							hback-porch = <0x1c>;
							hfront-porch = <0x28>;
							vback-porch = <0x26>;
							vfront-porch = <0xc8>;
							hsync-len = <0x08>;
							vsync-len = <0x08>;
							phandle = <0x42>;
						};
					};
				};
			};
		};
	};

	fragment@12 {
		target = <0xffffffff>;

		__overlay__ {
		};
	};

	fragment@13 {
		target = <0xffffffff>;

		__overlay__ {
			hardware = "mt8781";
		};
	};

	fragment@14 {
		target = <0xffffffff>;

		__overlay__ {
			compatible = "mediatek,pwm-leds";

			backlight {
				led_mode = <0x05>;
				gate_enable = <0x01>;
				pwms = <0xffffffff 0x00 0x99d9>;
				pwm_config = <0x00 0x01 0x00 0x00 0x00>;
			};
		};
	};

	fragment@15 {
		target = <0xffffffff>;

		__overlay__ {

			lcd_bias_enp1_gpio {
				phandle = <0x43>;

				pins_cmd_dat {
					pinmux = <0x2600>;
					slew-rate = <0x01>;
					output-high;
				};
			};

			lcd_bias_enp0_gpio {
				phandle = <0x44>;

				pins_cmd_dat {
					pinmux = <0x2600>;
					slew-rate = <0x01>;
					output-low;
				};
			};

			lcd_bias_enn1_gpio {
				phandle = <0x45>;

				pins_cmd_dat {
					pinmux = <0x2700>;
					slew-rate = <0x01>;
					output-high;
				};
			};

			lcd_bias_enn0_gpio {
				phandle = <0x46>;

				pins_cmd_dat {
					pinmux = <0x2700>;
					slew-rate = <0x01>;
					output-low;
				};
			};

			lcm_led_en1_gpio {
				phandle = <0x47>;

				pins_cmd_dat {
					pinmux = <0xc00>;
					slew-rate = <0x01>;
					output-high;
				};
			};

			lcm_led_en0_gpio {
				phandle = <0x48>;

				pins_cmd_dat {
					pinmux = <0xc00>;
					slew-rate = <0x01>;
					output-low;
				};
			};

			lcm_rst_out1_gpio {
				phandle = <0x49>;

				pins_cmd_dat {
					pinmux = <0x5500>;
					slew-rate = <0x01>;
					output-high;
				};
			};

			lcm_rst_out0_gpio {
				phandle = <0x4a>;

				pins_cmd_dat {
					pinmux = <0x5500>;
					slew-rate = <0x01>;
					output-low;
				};
			};

			lcm_dsi_te {
				phandle = <0x4b>;

				pins_cmd_dat {
					pinmux = <0x5301>;
				};
			};

			lcd_pwr_1v8_en_gpio {
				phandle = <0x4c>;

				pins_cmd_dat {
					pinmux = <0x3400>;
				};
			};

			lcd_pwr_3v3_en_gpio {
				phandle = <0x4d>;
			};

			tp_rst_gpio {
				phandle = <0x4e>;

				pins_cmd_dat {
					pinmux = <0x9800>;
				};
			};
		};
	};

	fragment@16 {
		target = <0xffffffff>;

		__overlay__ {
			pinctrl-names = "lcd_bias_enp1_gpio\0lcd_bias_enp0_gpio\0lcd_bias_enn1_gpio\0lcd_bias_enn0_gpio\0lcm_led_en1_gpio\0lcm_led_en0_gpio\0lcm_rst_out1_gpio\0lcm_rst_out0_gpio\0mode_te_te\0lcd_pwr_1v8_en_gpio\0lcd_pwr_3v3_en_gpio\0tp_rst_gpio";
			pinctrl-0 = <0x43>;
			pinctrl-1 = <0x44>;
			pinctrl-2 = <0x45>;
			pinctrl-3 = <0x46>;
			pinctrl-4 = <0x47>;
			pinctrl-5 = <0x48>;
			pinctrl-6 = <0x49>;
			pinctrl-7 = <0x4a>;
			pinctrl-8 = <0x4b>;
			pinctrl-9 = <0x4c>;
			pinctrl-10 = <0x4d>;
			pinctrl-11 = <0x4e>;
			status = "okay";
		};
	};

	fragment@17 {
		target = <0xffffffff>;

		__overlay__ {
			pinctrl-names = "lcm_rst_out1_gpio\0lcm_rst_out0_gpio\0mode_te_te";
			pinctrl-0 = <0x49>;
			pinctrl-1 = <0x4a>;
			pinctrl-2 = <0x4b>;
			status = "okay";
		};
	};

	fragment@18 {
		target = <0xffffffff>;

		__overlay__ {
			status = "okay";
			#address-cells = <0x01>;
			#size-cells = <0x00>;

			panel1@0 {
				compatible = "wb,drm_lcm";
				reg = <0x00>;
				pinctrl-names = "default";

				port {

					endpoint {
						remote-endpoint = <0x4f>;
						phandle = <0x50>;
					};
				};
			};

			ports {

				port {

					endpoint {
						remote-endpoint = <0x50>;
						phandle = <0x4f>;
					};
				};
			};
		};
	};

	fragment@19 {
		target = <0xffffffff>;

		__overlay__ {

			gpio-keys {
				compatible = "gpio-keys";
				phandle = <0x6d>;

				lid {
					label = "Lid";
					gpios = <0xffffffff 0x00 0x01>;
					linux,code = <0x00>;
					linux,input-type = <0x05>;
					gpio-key,wakeup;
				};
			};
		};
	};

	fragment@20 {
		target = <0xffffffff>;

		__overlay__ {

			gps_default {
				phandle = <0x52>;
			};

			gps_l1_lna@0 {
				phandle = <0x53>;

				pins_cmd_dat {
					pinmux = <0x1900>;
					output-low;
				};
			};

			gps_l1_lna@1 {
				phandle = <0x54>;

				pins_cmd_dat {
					pinmux = <0x1902>;
				};
			};

			gps_l1_lna@2 {
				phandle = <0x55>;

				pins_cmd_dat {
					pinmux = <0x1900>;
					output-high;
				};
			};

			gps_l5_lna@0 {
				phandle = <0x56>;

				pins_cmd_dat {
					pinmux = <0x1a00>;
					output-low;
				};
			};

			gps_l5_lna@1 {
				phandle = <0x57>;

				pins_cmd_dat {
					pinmux = <0x1a02>;
				};
			};

			gps_l5_lna@2 {
				phandle = <0x58>;

				pins_cmd_dat {
					pinmux = <0x1a00>;
					output-high;
				};
			};
		};
	};

	fragment@21 {
		target = <0xffffffff>;

		__overlay__ {
			pinctrl-names = "default";
			pinctrl-0 = <0x51>;
			docking_eint_gpio = <0xffffffff 0x0a 0x00>;
			interrupt-parent = <0xffffffff>;
			interrupts = <0x0a 0x08 0x0a 0x00>;
		};
	};

	fragment@22 {
		target = <0xffffffff>;

		__overlay__ {

			docking_eint_default {
				phandle = <0x51>;

				pins_cmd_dat {
					pinmux = <0xa00>;
					slew-rate = <0x00>;
					bias-pull-up;
				};
			};
		};
	};

	fragment@23 {
		target = <0xffffffff>;

		__overlay__ {
			compatible = "cust,cust_gpios";
			gpio_it6112_en = <0xffffffff 0x25 0x00>;
			gpio_bias_pos = <0xffffffff 0x26 0x00>;
			gpio_bias_neg = <0xffffffff 0x27 0x00>;
			gpio_lcm_1v8 = <0xffffffff 0x34 0x00>;
			gpio_lcm_rst = <0xffffffff 0x55 0x00>;
			gpio_tp_rst = <0xffffffff 0x98 0x00>;
			gpio_otg_5v_en = <0xffffffff 0x24 0x00>;
			gpio_docking_en = <0xffffffff 0x22 0x00>;
			gpio_usb_switch = <0xffffffff 0x29 0x00>;
			gpio_auhpr_spk_sw = <0xffffffff 0x0f 0x00>;
			gpio_usb_hp_sw = <0xffffffff 0x35 0x00>;
			status = "okay";
		};
	};

	fragment@24 {
		target = <0xffffffff>;

		__overlay__ {
			pinctrl-names = "default\0gps_l1_lna_disable\0gps_l1_lna_dsp_ctrl\0gps_l1_lna_enable\0gps_l5_lna_disable\0gps_l5_lna_dsp_ctrl\0gps_l5_lna_enable";
			pinctrl-0 = <0x52>;
			pinctrl-1 = <0x53>;
			pinctrl-2 = <0x54>;
			pinctrl-3 = <0x55>;
			pinctrl-4 = <0x56>;
			pinctrl-5 = <0x57>;
			pinctrl-6 = <0x58>;
			status = "okay";
		};
	};

	fragment@25 {
		target = <0xffffffff>;

		__overlay__ {
		};
	};

	fragment@26 {
		target = <0xffffffff>;

		__overlay__ {

			i2c0_pull_down_ctrl {
				phandle = <0x6e>;

				pins_cmd_dat {
					pinmux = <0x8201 0x8301>;
					slew-rate = <0x00>;
					bias-pull-down;
				};
			};

			i2c0_pull_up_ctrl {
				phandle = <0x6f>;

				pins_cmd_dat {
					pinmux = <0x8201 0x8301>;
					slew-rate = <0x00>;
					bias-pull-up;
				};
			};
		};
	};

	fragment@27 {
		target = <0xffffffff>;

		__overlay__ {

			aw87xxx@58 {
				compatible = "awinic,aw87xxx_pa";
				reg = <0x58>;
				dev_index = <0x00>;
				status = "okay";
			};

			aw87xxx@59 {
				compatible = "awinic,aw87xxx_pa";
				reg = <0x59>;
				dev_index = <0x03>;
				status = "okay";
			};
		};
	};

	fragment@28 {
		target = <0xffffffff>;

		__overlay__ {

			it6112@56 {
				compatible = "ite,it6112";
				reg = <0x56>;
				status = "okay";
			};
		};
	};

	fragment@29 {
		target = <0xffffffff>;

		__overlay__ {

			aw87xxx@58 {
				compatible = "awinic,aw87xxx_pa";
				reg = <0x58>;
				dev_index = <0x01>;
				status = "okay";
			};

			aw87xxx@59 {
				compatible = "awinic,aw87xxx_pa";
				reg = <0x59>;
				dev_index = <0x02>;
				status = "okay";
			};
		};
	};

	fragment@30 {
		target = <0xffffffff>;

		__overlay__ {

			red {
				label = "red";
				gpios = <0xffffffff 0x2d 0x00>;
				default-state = "off";
			};

			green {
				label = "green";
				gpios = <0xffffffff 0x2c 0x00>;
				default-state = "off";
			};

			blue {
				label = "blue";
				gpios = <0xffffffff 0x2a 0x00>;
				default-state = "off";
			};
		};
	};

	fragment@31 {
		target = <0xffffffff>;

		__overlay__ {
			max_charger_voltage = <0xb71b00>;
		};
	};

	fragment@32 {
		target = <0xffffffff>;

		__overlay__ {
			pd_vbus_upper_bound = <0xb71b00>;
			dcs_chg1_charger_current = <0x2dc6c0>;
			dcs_chg2_charger_current = <0x2dc6c0>;
		};
	};

	fragment@33 {
		target = <0xffffffff>;

		__overlay__ {
			dcs_input_current = <0x5b8d80>;
			dcs_chg1_charger_current = <0x2dc6c0>;
			dcs_chg2_charger_current = <0x2dc6c0>;
		};
	};

	fragment@34 {
		target = <0xffffffff>;

		__overlay__ {
			dcs_input_current = <0x5b8d80>;
			dcs_chg1_charger_current = <0x2dc6c0>;
			dcs_chg2_charger_current = <0x2dc6c0>;
		};
	};

	fragment@35 {
		target = <0xffffffff>;

		__overlay__ {
			max_charger_voltage = <0xc65d40>;
			min_charger_voltage = "\0I>";
			charger_configuration = <0x00>;
			charger_unlimited;
			battery_cv = <0x401640>;
		};
	};

	fragment@36 {
		target = <0xffffffff>;

		__overlay__ {
			headset-eint-level-pol = <0x08>;
		};
	};

	fragment@37 {
		target = <0xffffffff>;

		__overlay__ {
			min-volt = <0x325aa0>;
			max-volt = <0x325aa0>;
		};
	};

	fragment@38 {
		target = <0xffffffff>;

		__overlay__ {
			host-index = <0x01>;
			status = "okay";
			pinctrl-names = "default\0state_uhs\0pull_down";
			pinctrl-0 = <0x59>;
			pinctrl-1 = <0x5a>;
			pinctrl-2 = <0x5b>;
			bus-width = <0x04>;
			max-frequency = <0xbebc200>;
			ocr-voltage = <0x30000>;
			cap-sd-highspeed;
			sd-uhs-sdr12;
			sd-uhs-sdr25;
			sd-uhs-sdr50;
			sd-uhs-sdr104;
			sd-uhs-ddr50;
			cd-debounce-delay-ms = <0x00>;
			cd-gpios = <0xffffffff 0x07 0x00>;
			vmmc-supply = <0xffffffff>;
			vqmmc-supply = <0xffffffff>;
			no-mmc;
			dvfsrc-vcore-supply = <0xffffffff>;
			req-vcore = <0x9eb10>;
		};
	};

	fragment@39 {
		target = <0xffffffff>;

		__overlay__ {

			mmc1default {
				phandle = <0x59>;

				pins_cmd_dat {
					pinmux = <0x4901 0x4a01 0x4b01 0x4c01 0x4801>;
					input-enable;
					drive-strength = <0x03>;
					bias-pull-up = <0x65>;
				};

				pins_clk {
					pinmux = <0x4701>;
					drive-strength = <0x03>;
					bias-pull-down = <0x66>;
				};
			};

			mmc1@0 {
				phandle = <0x5a>;

				pins_cmd_dat {
					pinmux = <0x4901 0x4a01 0x4b01 0x4c01 0x4801>;
					input-enable;
					drive-strength = <0x03>;
					bias-pull-up = <0x65>;
				};

				pins_clk {
					pinmux = <0x4701>;
					drive-strength = <0x03>;
					bias-pull-down = <0x66>;
				};
			};

			mmc1@1 {
				phandle = <0x5b>;

				pins_cmd_dat {
					pinmux = <0x4901 0x4a01 0x4b01 0x4c01 0x4801>;
					input-enable;
					drive-strength = <0x03>;
					bias-pull-down = <0x66>;
				};

				pins_clk {
					pinmux = <0x4701>;
					drive-strength = <0x03>;
					bias-pull-down = <0x66>;
				};
			};
		};
	};

	fragment@40 {
		target = <0xffffffff>;

		__overlay__ {
			status = "okay";

			aw35615@22 {
				pinctrl-names = "int_n_pullup";
				pinctrl-0 = <0x5c>;
				compatible = "awinic,aw35615";
				reg = <0x22>;
				awinic,int_n = <0xffffffff 0x2e 0x00>;
				aw35615,snk_pdo_size = <0x01>;
				aw35615,snk_pdo_vol = <0x2328>;
				aw35615,snk_pdo_cur = <0x7d0>;
				aw35615,src_pdo_size = <0x01>;
				aw35615,src_pdo_vol = <0x1388>;
				aw35615,src_pdo_cur = <0x3e8>;
				aw35615,snk_tog_time = <0x38>;
				aw35615,src_tog_time = <0x24>;
				status = "okay";
			};
		};
	};

	fragment@41 {
		target = <0xffffffff>;

		__overlay__ {

			int_n_pull_up_ctrl {
				phandle = <0x5c>;

				pins_cmd_dat {
					pinmux = <0x2e00>;
					slew-rate = <0x00>;
					bias-pull-up;
				};
			};
		};
	};

	fragment@42 {
		target = <0xffffffff>;

		__overlay__ {
			status = "okay";
			pinctrl-names = "default";
			pinctrl-0 = <0x5d>;

			himax@0 {
				compatible = "himax,hxcommon";
				reg = <0x00>;
				status = "ok";
				pinctrl-names = "spi_pull_down\0spi_pull_up";
				pinctrl-0 = <0x5e>;
				pinctrl-1 = <0x5f>;
				spi-max-frequency = <0x927c00>;
				spi-cpha;
				interrupt-parent = <0xffffffff>;
				himax,rst-gpio = <0xffffffff 0x98 0x00>;
				himax,irq-gpio = <0xffffffff 0x09 0x00>;
				himax,panel-coords = <0x00 0x4b0 0x00 0x7d0>;
				himax,display-coords = <0x00 0x4b0 0x00 0x7d0>;
				report_type = <0x01>;
			};
		};
	};

	fragment@43 {
		target = <0xffffffff>;

		__overlay__ {

			spi0@1 {
				phandle = <0x5d>;

				pins_cmd_dat {
					pinmux = <0x1e01 0x2001 0x2101>;
					drive-strength = <0x02>;
				};
			};

			himax_spi_pull_down_ctrl {
				phandle = <0x5e>;

				pins_cmd_dat {
					pinmux = <0x1f00>;
					output-low;
				};
			};

			himax_spi_pull_up_ctrl {
				phandle = <0x5f>;

				pins_cmd_dat {
					pinmux = <0x1f01>;
					drive-strength = <0x02>;
				};
			};
		};
	};

	fragment@44 {
		target = <0xffffffff>;

		__overlay__ {
			GPIO_SIM1_HOT_PLUG = <0xffffffff 0x17 0x00>;
			GPIO_SIM2_HOT_PLUG = <0xffffffff 0x18 0x00>;
			GPIO_SIM1_SCLK = <0xffffffff 0x4d 0x00>;
			GPIO_SIM1_SRST = <0xffffffff 0x4e 0x00>;
			GPIO_SIM1_SIO = <0xffffffff 0x4f 0x00>;
			GPIO_SIM2_SCLK = <0xffffffff 0x50 0x00>;
			GPIO_SIM2_SRST = <0xffffffff 0x51 0x00>;
			GPIO_SIM2_SIO = <0xffffffff 0x52 0x00>;
			GPIO_FDD_BAND_SUPPORT_DETECT_1ST_PIN = <0xffffffff 0x6f 0x00>;
		};
	};

	fragment@45 {
		target = <0xffffffff>;

		__overlay__ {
			gpio_init_default = <0x00 0x00 0x00 0x00 0x01 0x01 0x01 0x01 0x00 0x00 0x00 0x01 0x00 0x01 0x02 0x00 0x00 0x00 0x01 0x00 0x01 0x03 0x00 0x00 0x00 0x01 0x00 0x01 0x04 0x00 0x00 0x00 0x01 0x01 0x01 0x05 0x00 0x00 0x00 0x01 0x01 0x01 0x06 0x00 0x00 0x00 0x01 0x01 0x01 0x07 0x00 0x00 0x00 0x00 0x00 0x01 0x08 0x00 0x00 0x00 0x01 0x00 0x01 0x09 0x00 0x00 0x00 0x01 0x01 0x01 0x0a 0x00 0x00 0x00 0x01 0x00 0x01 0x0b 0x00 0x00 0x00 0x01 0x01 0x01 0x0c 0x00 0x00 0x00 0x01 0x00 0x01 0x0d 0x00 0x00 0x00 0x01 0x01 0x01 0x0e 0x06 0x00 0x00 0x01 0x00 0x00 0x0f 0x00 0x01 0x00 0x01 0x00 0x00 0x10 0x00 0x01 0x00 0x01 0x00 0x00 0x11 0x00 0x01 0x00 0x01 0x00 0x00 0x12 0x00 0x01 0x00 0x01 0x00 0x00 0x13 0x00 0x01 0x00 0x01 0x00 0x00 0x14 0x00 0x01 0x00 0x01 0x00 0x00 0x15 0x00 0x01 0x00 0x01 0x00 0x00 0x16 0x00 0x01 0x00 0x01 0x00 0x00 0x17 0x01 0x00 0x00 0x01 0x01 0x00 0x18 0x01 0x00 0x00 0x01 0x01 0x00 0x19 0x02 0x00 0x00 0x01 0x00 0x01 0x1a 0x02 0x00 0x00 0x01 0x00 0x01 0x1b 0x00 0x00 0x00 0x01 0x00 0x00 0x1c 0x01 0x00 0x00 0x01 0x01 0x01 0x1d 0x01 0x00 0x00 0x00 0x00 0x01 0x1e 0x01 0x00 0x00 0x01 0x00 0x01 0x1f 0x01 0x00 0x00 0x01 0x00 0x01 0x20 0x01 0x00 0x00 0x00 0x00 0x01 0x21 0x01 0x00 0x00 0x01 0x00 0x01 0x22 0x00 0x01 0x00 0x01 0x00 0x00 0x23 0x00 0x01 0x00 0x01 0x00 0x00 0x24 0x00 0x01 0x00 0x01 0x00 0x00 0x25 0x00 0x01 0x00 0x01 0x00 0x00 0x26 0x00 0x01 0x00 0x01 0x00 0x01 0x27 0x00 0x01 0x00 0x01 0x00 0x01 0x28 0x00 0x01 0x00 0x01 0x00 0x01 0x29 0x00 0x01 0x00 0x01 0x00 0x01 0x2a 0x00 0x01 0x00 0x01 0x00 0x00 0x2b 0x00 0x01 0x00 0x01 0x00 0x00 0x2c 0x00 0x01 0x00 0x01 0x00 0x00 0x2d 0x00 0x01 0x00 0x01 0x00 0x00 0x2e 0x00 0x00 0x00 0x01 0x01 0x00 0x2f 0x00 0x01 0x00 0x01 0x00 0x00 0x30 0x00 0x01 0x00 0x01 0x00 0x00 0x31 0x00 0x01 0x00 0x01 0x00 0x00 0x32 0x00 0x01 0x00 0x01 0x00 0x01 0x33 0x00 0x01 0x00 0x01 0x00 0x01 0x34 0x00 0x01 0x00 0x01 0x00 0x01 0x35 0x00 0x01 0x00 0x01 0x00 0x01 0x36 0x00 0x00 0x00 0x01 0x00 0x00 0x37 0x00 0x00 0x00 0x01 0x00 0x00 0x38 0x00 0x00 0x00 0x01 0x00 0x00 0x39 0x00 0x00 0x00 0x01 0x00 0x00 0x3a 0x00 0x00 0x00 0x01 0x00 0x00 0x3b 0x00 0x00 0x00 0x01 0x00 0x00 0x3c 0x00 0x00 0x00 0x01 0x00 0x00 0x3d 0x00 0x00 0x00 0x01 0x00 0x00 0x3e 0x00 0x00 0x00 0x01 0x00 0x00 0x3f 0x00 0x00 0x00 0x01 0x00 0x00 0x40 0x00 0x00 0x00 0x01 0x00 0x00 0x41 0x00 0x00 0x00 0x01 0x00 0x00 0x42 0x01 0x00 0x00 0x01 0x01 0x00 0x43 0x01 0x00 0x00 0x01 0x01 0x01 0x44 0x00 0x00 0x00 0x01 0x00 0x01 0x45 0x00 0x00 0x00 0x01 0x01 0x01 0x4d 0x01 0x00 0x00 0x00 0x00 0x01 0x4e 0x01 0x00 0x00 0x00 0x00 0x01 0x4f 0x01 0x00 0x00 0x01 0x01 0x01 0x50 0x01 0x00 0x00 0x00 0x00 0x01 0x51 0x01 0x00 0x00 0x00 0x00 0x01 0x52 0x01 0x00 0x00 0x01 0x01 0x01 0x53 0x01 0x00 0x00 0x01 0x00 0x01 0x54 0x01 0x00 0x00 0x00 0x00 0x01 0x55 0x00 0x01 0x00 0x01 0x00 0x01 0x56 0x00 0x01 0x00 0x01 0x00 0x00 0x57 0x01 0x00 0x00 0x01 0x00 0x00 0x58 0x01 0x00 0x00 0x01 0x00 0x00 0x59 0x01 0x00 0x00 0x01 0x00 0x00 0x5a 0x01 0x00 0x00 0x01 0x00 0x00 0x5b 0x01 0x00 0x00 0x01 0x00 0x00 0x5c 0x01 0x00 0x00 0x01 0x00 0x00 0x5d 0x01 0x00 0x00 0x01 0x00 0x00 0x5e 0x01 0x00 0x00 0x01 0x00 0x00 0x5f 0x01 0x00 0x00 0x01 0x00 0x00 0x60 0x01 0x00 0x00 0x01 0x00 0x00 0x61 0x01 0x00 0x00 0x01 0x00 0x00 0x62 0x01 0x00 0x00 0x01 0x00 0x00 0x63 0x01 0x00 0x00 0x01 0x00 0x00 0x64 0x00 0x00 0x00 0x01 0x00 0x00 0x65 0x00 0x00 0x00 0x01 0x00 0x00 0x66 0x01 0x00 0x00 0x01 0x00 0x00 0x67 0x02 0x00 0x00 0x01 0x00 0x00 0x68 0x02 0x00 0x00 0x00 0x00 0x00 0x69 0x01 0x00 0x00 0x01 0x00 0x00 0x6a 0x01 0x00 0x00 0x01 0x00 0x00 0x6b 0x01 0x00 0x00 0x01 0x00 0x00 0x6c 0x01 0x00 0x00 0x01 0x00 0x00 0x6d 0x01 0x00 0x00 0x01 0x00 0x00 0x6e 0x01 0x00 0x00 0x01 0x00 0x00 0x6f 0x00 0x00 0x00 0x00 0x00 0x00 0x70 0x01 0x00 0x00 0x00 0x00 0x00 0x71 0x01 0x00 0x00 0x01 0x00 0x00 0x72 0x01 0x00 0x00 0x00 0x00 0x00 0x73 0x01 0x00 0x00 0x01 0x00 0x00 0x74 0x01 0x00 0x00 0x00 0x00 0x00 0x75 0x01 0x00 0x00 0x01 0x00 0x00 0x76 0x01 0x00 0x00 0x00 0x00 0x00 0x77 0x01 0x00 0x00 0x01 0x00 0x00 0x78 0x01 0x00 0x00 0x00 0x00 0x00 0x79 0x01 0x00 0x00 0x01 0x00 0x00 0x7a 0x01 0x00 0x00 0x00 0x00 0x00 0x7b 0x01 0x00 0x00 0x00 0x00 0x00 0x7c 0x01 0x00 0x00 0x01 0x00 0x00 0x7d 0x01 0x00 0x00 0x01 0x00 0x00 0x7e 0x01 0x00 0x00 0x01 0x00 0x00 0x7f 0x01 0x00 0x00 0x01 0x00 0x00 0x80 0x01 0x00 0x00 0x01 0x00 0x00 0x81 0x01 0x00 0x00 0x01 0x00 0x00 0x82 0x01 0x00 0x00 0x01 0x01 0x01 0x83 0x01 0x00 0x00 0x01 0x01 0x01 0x84 0x01 0x00 0x00 0x01 0x01 0x00 0x85 0x01 0x00 0x00 0x01 0x01 0x00 0x86 0x01 0x00 0x00 0x01 0x01 0x01 0x87 0x01 0x00 0x00 0x01 0x01 0x01 0x88 0x01 0x00 0x00 0x01 0x01 0x01 0x89 0x01 0x00 0x00 0x01 0x01 0x01 0x8a 0x01 0x00 0x00 0x01 0x01 0x01 0x8b 0x01 0x00 0x00 0x01 0x01 0x01 0x8c 0x01 0x00 0x00 0x01 0x01 0x01 0x8d 0x01 0x00 0x00 0x01 0x01 0x01 0x8e 0x01 0x00 0x00 0x01 0x01 0x01 0x8f 0x01 0x00 0x00 0x01 0x01 0x01 0x90 0x01 0x00 0x00 0x01 0x01 0x01 0x91 0x01 0x00 0x00 0x01 0x01 0x01 0x92 0x01 0x00 0x00 0x01 0x01 0x01 0x93 0x01 0x00 0x00 0x01 0x01 0x01 0x94 0x02 0x00 0x00 0x01 0x01 0x01 0x95 0x02 0x00 0x00 0x01 0x01 0x01 0x96 0x00 0x01 0x00 0x01 0x00 0x01 0x97 0x00 0x01 0x01 0x01 0x00 0x01 0x98 0x00 0x01 0x00 0x01 0x00 0x01 0x99 0x00 0x00 0x00 0x01 0x00 0x01 0x9a 0x00 0x01 0x00 0x01 0x00 0x01 0x9b 0x00 0x01 0x00 0x01 0x00 0x01 0x9c 0x00 0x01 0x00 0x01 0x00 0x01 0x9d 0x00 0x01 0x00 0x01 0x00 0x01 0x9e 0x00 0x01 0x00 0x01 0x00 0x00 0x9f 0x00 0x01 0x00 0x01 0x00 0x00 0xa0 0x01 0x00 0x00 0x00 0x00 0x01 0xa1 0x01 0x00 0x00 0x00 0x00 0x01 0xa2 0x01 0x00 0x00 0x00 0x00 0x01 0xa3 0x01 0x00 0x00 0x01 0x00 0x01 0xa4 0x01 0x00 0x00 0x00 0x00 0x01 0xa5 0x01 0x00 0x00 0x00 0x00 0x01 0xa6 0x01 0x00 0x00 0x00 0x00 0x01 0xa7 0x01 0x00 0x00 0x01 0x00 0x01 0xa8 0x01 0x00 0x00 0x00 0x00 0x00 0xa9 0x01 0x00 0x00 0x00 0x00 0x01 0xaa 0x01 0x00 0x00 0x00 0x00 0x01 0xab 0x01 0x00 0x00 0x00 0x00 0x01 0xac 0x01 0x00 0x00 0x00 0x00 0x01 0xad 0x01 0x00 0x00 0x01 0x00 0x01 0xae 0x01 0x00 0x00 0x01 0x00 0x01 0xaf 0x01 0x00 0x00 0x01 0x00 0x01 0xb0 0x01 0x00 0x00 0x01 0x00 0x01 0xb1 0x00 0x00 0x00 0x01 0x00 0x00 0xb2 0x00 0x00 0x00 0x01 0x00 0x00 0xb3 0x00 0x00 0x00 0x01 0x00 0x00 0xb4 0x00 0x00 0x00 0x01 0x00 0x00 0xb5 0x00 0x00 0x00 0x01 0x00 0x00 0xb6 0x00 0x00 0x00 0x01 0x00 0x00 0xb7 0x00 0x00 0x00 0x01 0x00 0x00 0xb8 0x00 0x00 0x00 0x01 0x00 0x00 0xb9 0x00 0x00 0x00 0x01 0x00 0x00 0xba 0x01 0x00 0x00 0x01 0x01 0x01 0xbb 0x01 0x00 0x00 0x01 0x01 0x01 0xbc 0x00 0x00 0x00 0x01 0x00 0x00 0xbd 0x00 0x00 0x00 0x01 0x00 0x00 0xbe 0x00 0x00 0x00 0x01 0x00 0x00 0xbf 0x00 0x00 0x00 0x01 0x00 0x00 0xc0 0x00 0x00 0x00 0x01 0x00 0x00 0xc1 0x00 0x00 0x00 0x01 0x00 0x00 0xc2 0x00 0x00 0x00 0x01 0x00 0x00 0xc3 0x00 0x00 0x00 0x01 0x00 0x00 0xc4 0x00 0x00 0x00 0x01 0x00 0x00 0xc5 0x00 0x00 0x00 0x01 0x00 0x00 0xc6 0x00 0x00 0x00 0x01 0x00 0x00 0xc7 0x00 0x00 0x00 0x01 0x00 0x00 0xc8 0x00 0x00 0x00 0x01 0x00 0x00 0xc9 0x00 0x00 0x00 0x01 0x00 0x00 0xca 0x00 0x00 0x00 0x01 0x00 0x00 0xcb 0x00 0x00 0x00 0x01 0x00 0x00 0xcc 0x00 0x00 0x00 0x01 0x00 0x00 0xcd 0x00 0x00 0x00 0x01 0x00 0x00 0xce 0x00 0x00 0x00 0x01 0x00 0x00 0xcf 0x00 0x00 0x00 0x01 0x00 0x00 0xd0 0x00 0x00 0x00 0x01 0x00 0x00 0xd1 0x00 0x00 0x00 0x01 0x00 0x00 0xd2 0x00 0x00 0x00 0x01 0x00 0x00 0xd3 0x00 0x00 0x00 0x01 0x00 0x00 0xd4 0x00 0x00 0x00 0x01 0x00 0x00 0xd5 0x00 0x00 0x00 0x01 0x00 0x00 0xd6 0x00 0x00 0x00 0x01 0x00 0x00 0xd7 0x00 0x00 0x00 0x01 0x00 0x00 0xd8 0x00 0x00 0x00 0x01 0x00 0x00 0xd9 0x00 0x00 0x00 0x01 0x00 0x00 0xda 0x00 0x00 0x00 0x01 0x00 0x00 0xdb 0x00 0x00 0x00 0x01 0x00 0x00 0xdc 0x00 0x00 0x00 0x01 0x00 0x00 0xdd 0x00 0x00 0x00 0x01 0x00 0x00>;
		};
	};

	fragment@46 {
		target = <0xffffffff>;

		__overlay__ {
			interrupt-parent = <0xffffffff>;
			interrupts = <0x04 0x08>;
			status = "okay";
		};
	};

	fragment@47 {
		target = <0xffffffff>;

		__overlay__ {
			interrupt-parent = <0xffffffff>;
			interrupts = <0x05 0x02>;
			status = "okay";
		};
	};

	fragment@48 {
		target = <0xffffffff>;

		__overlay__ {
			interrupt-parent = <0xffffffff>;
			interrupts = <0x06 0x08>;
			status = "okay";
		};
	};

	fragment@49 {
		target = <0xffffffff>;

		__overlay__ {
			interrupt-parent = <0xffffffff>;
			interrupts = <0x09 0x02>;
			status = "okay";
		};
	};

	fragment@50 {
		target = <0xffffffff>;

		__overlay__ {
			interrupt-parent = <0xffffffff>;
			interrupts = <0x53 0x01>;
			status = "okay";
		};
	};

	fragment@51 {
		target = <0xffffffff>;

		__overlay__ {
			compatible = "mediatek,md1_sim1_hot_plug_eint-eint";
			interrupts = <0x00 0x08>;
			debounce = <0x00 0x2710>;
			dedicated = <0x00 0x00>;
			src_pin = <0x00 0x01>;
			sockettype = <0x00 0x00>;
			status = "okay";
		};
	};

	fragment@52 {
		target = <0xffffffff>;

		__overlay__ {
			compatible = "mediatek,md1_sim2_hot_plug_eint-eint";
			interrupts = <0x01 0x08>;
			debounce = <0x01 0x2710>;
			dedicated = <0x01 0x00>;
			src_pin = <0x01 0x02>;
			sockettype = <0x01 0x00>;
			status = "okay";
		};
	};

	fragment@53 {
		target = <0xffffffff>;

		__overlay__ {
			mediatek,key-debounce = <0x400>;
			mediatek,sw-pwrkey = <0x74>;
			mediatek,hw-pwrkey = <0x08>;
			mediatek,use-extend-type = <0x00>;
			mediatek,hw-map-num = <0x48>;
			mediatek,hw-init-map = <0x73 0x72 0x00 0x00 0x00 0x00 0x00 0x00 0x00 0x00 0x00 0x00 0x00 0x00 0x00 0x00 0x00 0x00 0x00 0x00 0x00 0x00 0x00 0x00 0x00 0x00 0x00 0x00 0x00 0x00 0x00 0x00 0x00 0x00 0x00 0x00 0x00 0x00 0x00 0x00 0x00 0x00 0x00 0x00 0x00 0x00 0x00 0x00 0x00 0x00 0x00 0x00 0x00 0x00 0x00 0x00 0x00 0x00 0x00 0x00 0x00 0x00 0x00 0x00 0x00 0x00 0x00 0x00 0x00 0x00 0x00 0x00>;
			mediatek,pwrkey-eint-gpio = <0x00>;
			mediatek,pwkey-gpio-din = <0x00>;
			mediatek,hw-dl-key0 = <0x01>;
			mediatek,hw-dl-key1 = <0x00>;
			mediatek,hw-dl-key2 = <0x08>;
			mediatek,hw-recovery-key = <0x00>;
			mediatek,hw-factory-key = <0x01>;
			status = "okay";
		};
	};

	__symbols__ {
		camera_pins_cam0_rst_0 = "/fragment@0/__overlay__/cam0@0";
		camera_pins_cam0_rst_1 = "/fragment@0/__overlay__/cam0@1";
		camera_pins_cam0_pnd_0 = "/fragment@0/__overlay__/cam0@2";
		camera_pins_cam0_pnd_1 = "/fragment@0/__overlay__/cam0@3";
		camera_pins_cam1_rst_0 = "/fragment@0/__overlay__/cam1@0";
		camera_pins_cam1_rst_1 = "/fragment@0/__overlay__/cam1@1";
		camera_pins_cam1_pnd_0 = "/fragment@0/__overlay__/cam1@2";
		camera_pins_cam1_pnd_1 = "/fragment@0/__overlay__/cam1@3";
		camera_pins_cam2_rst_0 = "/fragment@0/__overlay__/cam2@0";
		camera_pins_cam2_rst_1 = "/fragment@0/__overlay__/cam2@1";
		camera_pins_cam2_pnd_0 = "/fragment@0/__overlay__/cam2@2";
		camera_pins_cam2_pnd_1 = "/fragment@0/__overlay__/cam2@3";
		camera_pins_cam0_mclk_off = "/fragment@0/__overlay__/camera_pins_cam0_mclk_off";
		camera_pins_cam0_mclk_2ma = "/fragment@0/__overlay__/camera_pins_cam0_mclk_2ma";
		camera_pins_cam0_mclk_4ma = "/fragment@0/__overlay__/camera_pins_cam0_mclk_4ma";
		camera_pins_cam0_mclk_6ma = "/fragment@0/__overlay__/camera_pins_cam0_mclk_6ma";
		camera_pins_cam0_mclk_8ma = "/fragment@0/__overlay__/camera_pins_cam0_mclk_8ma";
		camera_pins_cam1_mclk_off = "/fragment@0/__overlay__/camera_pins_cam1_mclk_off";
		camera_pins_cam1_mclk_2ma = "/fragment@0/__overlay__/camera_pins_cam1_mclk_2ma";
		camera_pins_cam1_mclk_4ma = "/fragment@0/__overlay__/camera_pins_cam1_mclk_4ma";
		camera_pins_cam1_mclk_6ma = "/fragment@0/__overlay__/camera_pins_cam1_mclk_6ma";
		camera_pins_cam1_mclk_8ma = "/fragment@0/__overlay__/camera_pins_cam1_mclk_8ma";
		camera_pins_cam2_mclk_off = "/fragment@0/__overlay__/camera_pins_cam2_mclk_off";
		camera_pins_cam2_mclk_2ma = "/fragment@0/__overlay__/camera_pins_cam2_mclk_2ma";
		camera_pins_cam2_mclk_4ma = "/fragment@0/__overlay__/camera_pins_cam2_mclk_4ma";
		camera_pins_cam2_mclk_6ma = "/fragment@0/__overlay__/camera_pins_cam2_mclk_6ma";
		camera_pins_cam2_mclk_8ma = "/fragment@0/__overlay__/camera_pins_cam2_mclk_8ma";
		camera_pins_default = "/fragment@0/__overlay__/camdefault";
		camera_pins_cam0_ldo_vcama_0 = "/fragment@0/__overlay__/vcama@0";
		camera_pins_cam0_ldo_vcama_1 = "/fragment@0/__overlay__/vcama@1";
		camera_pins_cam0_ldo_vcamio_0 = "/fragment@0/__overlay__/vcamio@0";
		camera_pins_cam0_ldo_vcamio_1 = "/fragment@0/__overlay__/vcamio@1";
		camera_pins_cam0_ldo_vcamd_0 = "/fragment@0/__overlay__/vcamd@0";
		camera_pins_cam0_ldo_vcamd_1 = "/fragment@0/__overlay__/vcamd@1";
		camera_pins_cam0_ldo_vcamaf_0 = "/fragment@0/__overlay__/vcamaf@0";
		camera_pins_cam0_ldo_vcamaf_1 = "/fragment@0/__overlay__/vcamaf@1";
		camera_pins_cam1_ldo_vcama_0 = "/fragment@0/__overlay__/vcama_1@0";
		camera_pins_cam1_ldo_vcama_1 = "/fragment@0/__overlay__/vcama_1@1";
		camera_pins_cam1_ldo_vcamio_0 = "/fragment@0/__overlay__/vcamio_1@0";
		camera_pins_cam1_ldo_vcamio_1 = "/fragment@0/__overlay__/vcamio_1@1";
		camera_pins_cam1_ldo_vcamd_0 = "/fragment@0/__overlay__/vcamd_1@0";
		camera_pins_cam1_ldo_vcamd_1 = "/fragment@0/__overlay__/vcamd_1@1";
		camera_pins_cam1_ldo_vcamaf_0 = "/fragment@0/__overlay__/vcamaf_1@0";
		camera_pins_cam1_ldo_vcamaf_1 = "/fragment@0/__overlay__/vcamaf_1@1";
		camera_pins_cam2_ldo_vcama_0 = "/fragment@0/__overlay__/vcama_2@0";
		camera_pins_cam2_ldo_vcama_1 = "/fragment@0/__overlay__/vcama_2@1";
		camera_pins_cam2_ldo_vcamio_0 = "/fragment@0/__overlay__/vcamio_2@0";
		camera_pins_cam2_ldo_vcamio_1 = "/fragment@0/__overlay__/vcamio_2@1";
		camera_pins_cam2_ldo_vcamd_0 = "/fragment@0/__overlay__/vcamd_2@0";
		camera_pins_cam2_ldo_vcamd_1 = "/fragment@0/__overlay__/vcamd_2@1";
		camera_pins_cam2_ldo_vcamaf_0 = "/fragment@0/__overlay__/vcamaf_2@0";
		camera_pins_cam2_ldo_vcamaf_1 = "/fragment@0/__overlay__/vcamaf_2@1";
		mtk_camera_eeprom2 = "/fragment@2/__overlay__/camera_eeprom2@51";
		camera_main_two_mtk = "/fragment@2/__overlay__/camera_main_two@10";
		camera_main_two_af_mtk = "/fragment@2/__overlay__/camera_main_two_af@0d";
		camera_main_three_af_mtk = "/fragment@2/__overlay__/camera_main_three_af@0c";
		mtk_camera_eeprom1 = "/fragment@3/__overlay__/camera_eeprom1@51";
		camera_sub_mtk = "/fragment@3/__overlay__/camera_sub@1a";
		mtk_camera_eeprom0 = "/fragment@4/__overlay__/camera_eeprom0@50";
		camera_main_mtk = "/fragment@4/__overlay__/camera_main@1a";
		camera_main_af_mtk = "/fragment@4/__overlay__/camera_main_af@72";
		camera_main = "/fragment@5/__overlay__/camera_main";
		camera_sub = "/fragment@5/__overlay__/camera_sub";
		camera_main_two = "/fragment@5/__overlay__/camera_main_two";
		lm3643 = "/fragment@6/__overlay__/lm3643@63";
		fl_core_0 = "/fragment@6/__overlay__/lm3643@63/flash@0/port@0/endpoint";
		fl_core_1 = "/fragment@6/__overlay__/lm3643@63/flash@1/port@1/endpoint";
		flashlight_0 = "/fragment@7/__overlay__/port@0/endpoint";
		flashlight_1 = "/fragment@7/__overlay__/port@1/endpoint";
		flashlights_cp2155_pins_hwen_high = "/fragment@9/__overlay__/hwen_high";
		flashlights_cp2155_pins_hwen_low = "/fragment@9/__overlay__/hwen_low";
		flashlights_cp2155_pins_mode_high = "/fragment@9/__overlay__/mode_high";
		flashlights_cp2155_pins_mode_low = "/fragment@9/__overlay__/mode_low";
		cust_lk_panel = "/fragment/__overlay__/lcds/cust_lk_panel";
		cust_lk_panel_timing = "/fragment/__overlay__/lcds/cust_lk_panel/display-timings/timing0";
		m100t_ft8201_xy2210d4001a_wuxga2000_pt2 = "/fragment/__overlay__/lcds/m100t_ft8201_xy2210d4001a_wuxga2000_pt2";
		m100t_ft8201_xy2210d4001a_wuxga2000_pt2_timing = "/fragment/__overlay__/lcds/m100t_ft8201_xy2210d4001a_wuxga2000_pt2/display-timings/timing0";
		m100t_jd9366tc_sq110aq7ez51394l501_wuxga2000_jst_864 = "/fragment/__overlay__/lcds/m100t_jd9366tc_sq110aq7ez51394l501_wuxga2000_jst_864";
		m100t_jd9366tc_sq110aq7ez51394l501_wuxga2000_jst_864_timing = "/fragment/__overlay__/lcds/m100t_jd9366tc_sq110aq7ez51394l501_wuxga2000_jst_864/display-timings/timing0";
		mtkfb_pins_lcd_bias_enp1 = "/fragment@15/__overlay__/lcd_bias_enp1_gpio";
		mtkfb_pins_lcd_bias_enp0 = "/fragment@15/__overlay__/lcd_bias_enp0_gpio";
		mtkfb_pins_lcd_bias_enn1 = "/fragment@15/__overlay__/lcd_bias_enn1_gpio";
		mtkfb_pins_lcd_bias_enn0 = "/fragment@15/__overlay__/lcd_bias_enn0_gpio";
		mtkfb_pins_lcm_led_en1 = "/fragment@15/__overlay__/lcm_led_en1_gpio";
		mtkfb_pins_lcm_led_en0 = "/fragment@15/__overlay__/lcm_led_en0_gpio";
		mtkfb_pins_lcm_rst_out1_gpio = "/fragment@15/__overlay__/lcm_rst_out1_gpio";
		mtkfb_pins_lcm_rst_out0_gpio = "/fragment@15/__overlay__/lcm_rst_out0_gpio";
		mtkfb_pins_lcm_dsi_te = "/fragment@15/__overlay__/lcm_dsi_te";
		mtkfb_pins_lcd_pwr_1v8_en = "/fragment@15/__overlay__/lcd_pwr_1v8_en_gpio";
		mtkfb_pins_lcd_pwr_3v3_en = "/fragment@15/__overlay__/lcd_pwr_3v3_en_gpio";
		mtkfb_pins_tp_rst_gpio = "/fragment@15/__overlay__/tp_rst_gpio";
		panel_in1 = "/fragment@18/__overlay__/panel1@0/port/endpoint";
		dsi_out = "/fragment@18/__overlay__/ports/port/endpoint";
		gpio_keys = "/fragment@19/__overlay__/gpio-keys";
		gps_pins_default = "/fragment@20/__overlay__/gps_default";
		gps_l1_lna_pins_ol = "/fragment@20/__overlay__/gps_l1_lna@0";
		gps_l1_lna_pins_dsp_ctrl = "/fragment@20/__overlay__/gps_l1_lna@1";
		gps_l1_lna_pins_oh = "/fragment@20/__overlay__/gps_l1_lna@2";
		gps_l5_lna_pins_ol = "/fragment@20/__overlay__/gps_l5_lna@0";
		gps_l5_lna_pins_dsp_ctrl = "/fragment@20/__overlay__/gps_l5_lna@1";
		gps_l5_lna_pins_oh = "/fragment@20/__overlay__/gps_l5_lna@2";
		docking_eint_default = "/fragment@22/__overlay__/docking_eint_default";
		i2c0_pull_down_ctrl = "/fragment@26/__overlay__/i2c0_pull_down_ctrl";
		i2c0_pull_up_ctrl = "/fragment@26/__overlay__/i2c0_pull_up_ctrl";
		mmc1_pins_default = "/fragment@39/__overlay__/mmc1default";
		mmc1_pins_uhs = "/fragment@39/__overlay__/mmc1@0";
		mmc1_pins_pull_down = "/fragment@39/__overlay__/mmc1@1";
		int_n_pull_up_ctrl = "/fragment@41/__overlay__/int_n_pull_up_ctrl";
		spi_pins_0 = "/fragment@43/__overlay__/spi0@1";
		himax_spi_pull_down_ctrl = "/fragment@43/__overlay__/himax_spi_pull_down_ctrl";
		himax_spi_pull_up_ctrl = "/fragment@43/__overlay__/himax_spi_pull_up_ctrl";
	};

	__fixups__ {
		pio = "/fragment@0:target:0\0/fragment@9:target:0\0/fragment@15:target:0\0/fragment@19/__overlay__/gpio-keys/lid:gpios:0\0/fragment@20:target:0\0/fragment@21/__overlay__:docking_eint_gpio:0\0/fragment@21/__overlay__:interrupt-parent:0\0/fragment@22:target:0\0/fragment@23/__overlay__:gpio_it6112_en:0\0/fragment@23/__overlay__:gpio_bias_pos:0\0/fragment@23/__overlay__:gpio_bias_neg:0\0/fragment@23/__overlay__:gpio_lcm_1v8:0\0/fragment@23/__overlay__:gpio_lcm_rst:0\0/fragment@23/__overlay__:gpio_tp_rst:0\0/fragment@23/__overlay__:gpio_otg_5v_en:0\0/fragment@23/__overlay__:gpio_docking_en:0\0/fragment@23/__overlay__:gpio_usb_switch:0\0/fragment@23/__overlay__:gpio_auhpr_spk_sw:0\0/fragment@23/__overlay__:gpio_usb_hp_sw:0\0/fragment@26:target:0\0/fragment@30/__overlay__/red:gpios:0\0/fragment@30/__overlay__/green:gpios:0\0/fragment@30/__overlay__/blue:gpios:0\0/fragment@38/__overlay__:cd-gpios:0\0/fragment@39:target:0\0/fragment@40/__overlay__/aw35615@22:awinic,int_n:0\0/fragment@41:target:0\0/fragment@42/__overlay__/himax@0:interrupt-parent:0\0/fragment@42/__overlay__/himax@0:himax,rst-gpio:0\0/fragment@42/__overlay__/himax@0:himax,irq-gpio:0\0/fragment@43:target:0\0/fragment@44/__overlay__:GPIO_SIM1_HOT_PLUG:0\0/fragment@44/__overlay__:GPIO_SIM2_HOT_PLUG:0\0/fragment@44/__overlay__:GPIO_SIM1_SCLK:0\0/fragment@44/__overlay__:GPIO_SIM1_SRST:0\0/fragment@44/__overlay__:GPIO_SIM1_SIO:0\0/fragment@44/__overlay__:GPIO_SIM2_SCLK:0\0/fragment@44/__overlay__:GPIO_SIM2_SRST:0\0/fragment@44/__overlay__:GPIO_SIM2_SIO:0\0/fragment@44/__overlay__:GPIO_FDD_BAND_SUPPORT_DETECT_1ST_PIN:0\0/fragment@46/__overlay__:interrupt-parent:0\0/fragment@47/__overlay__:interrupt-parent:0\0/fragment@48/__overlay__:interrupt-parent:0\0/fragment@49/__overlay__:interrupt-parent:0\0/fragment@50/__overlay__:interrupt-parent:0";
		kd_camera_hw1 = "/fragment@1:target:0";
		i2c2 = "/fragment@2:target:0";
		i2c4 = "/fragment@3:target:0";
		i2c8 = "/fragment@4:target:0";
		thermal_zones = "/fragment@5:target:0";
		i2c6 = "/fragment@6:target:0\0/fragment@29:target:0\0/fragment@40:target:0";
		mtk_composite_v4l2_1 = "/fragment@7:target:0";
		camera_af_hw_node = "/fragment@8:target:0";
		rt5133_ldo3 = "/fragment@8/__overlay__:camaf_m1_pmic-supply:0";
		rt5133_gpio1 = "/fragment@8/__overlay__:camaf_m2_pmic-supply:0\0/fragment@8/__overlay__:camaf_m3_pmic-supply:0";
		flashlights_cp2155 = "/fragment@10:target:0";
		mtk_gauge = "/fragment@11:target:0";
		chosen = "/fragment@12:target:0";
		android = "/fragment@13:target:0";
		mtk_leds = "/fragment@14:target:0";
		disp_pwm = "/fragment@14/__overlay__/backlight:pwms:0";
		mtkfb = "/fragment@16:target:0";
		dispsys_config = "/fragment@17:target:0";
		dsi0 = "/fragment@18:target:0";
		odm = "/fragment@19:target:0";
		extcon_usb = "/fragment@21:target:0";
		cust_gpios = "/fragment@23:target:0";
		gps = "/fragment@24:target:0";
		i2c0 = "/fragment@25:target:0";
		i2c1 = "/fragment@27:target:0";
		i2c3 = "/fragment@28:target:0";
		leds = "/fragment@30:target:0";
		lk_charger = "/fragment@31:target:0";
		pdc = "/fragment@32:target:0";
		pe2 = "/fragment@33:target:0";
		pe4 = "/fragment@34:target:0";
		charger = "/fragment@35:target:0";
		accdet = "/fragment@36:target:0";
		regulator_vibrator = "/fragment@37:target:0";
		mmc1 = "/fragment@38:target:0";
		mt6358_vmch_eint_low = "/fragment@38/__overlay__:vmmc-supply:0";
		mt6358_vmc_reg = "/fragment@38/__overlay__:vqmmc-supply:0";
		dvfsrc_vcore = "/fragment@38/__overlay__:dvfsrc-vcore-supply:0";
		spi0 = "/fragment@42:target:0";
		gpio_usage_mapping = "/fragment@44:target:0";
		gpio = "/fragment@45:target:0";
		subpmic_pmu_eint = "/fragment@46:target:0";
		rt5133_eint = "/fragment@47:target:0";
		smart_pa = "/fragment@48:target:0";
		touch = "/fragment@49:target:0";
		dsi_te = "/fragment@50:target:0";
		md1_sim1_hot_plug_eint = "/fragment@51:target:0";
		md1_sim2_hot_plug_eint = "/fragment@52:target:0";
		keypad = "/fragment@53:target:0";
	};

	__local_fixups__ {

		fragment@1 {

			__overlay__ {
				pinctrl-0 = <0x00>;
				pinctrl-1 = <0x00>;
				pinctrl-2 = <0x00>;
				pinctrl-3 = <0x00>;
				pinctrl-4 = <0x00>;
				pinctrl-5 = <0x00>;
				pinctrl-6 = <0x00>;
				pinctrl-7 = <0x00>;
				pinctrl-8 = <0x00>;
				pinctrl-9 = <0x00>;
				pinctrl-10 = <0x00>;
				pinctrl-11 = <0x00>;
				pinctrl-12 = <0x00>;
				pinctrl-13 = <0x00>;
				pinctrl-14 = <0x00>;
				pinctrl-15 = <0x00>;
				pinctrl-16 = <0x00>;
				pinctrl-17 = <0x00>;
				pinctrl-18 = <0x00>;
				pinctrl-19 = <0x00>;
				pinctrl-20 = <0x00>;
				pinctrl-21 = <0x00>;
				pinctrl-22 = <0x00>;
				pinctrl-23 = <0x00>;
				pinctrl-24 = <0x00>;
				pinctrl-25 = <0x00>;
				pinctrl-26 = <0x00>;
				pinctrl-27 = <0x00>;
				pinctrl-28 = <0x00>;
				pinctrl-29 = <0x00>;
				pinctrl-30 = <0x00>;
				pinctrl-31 = <0x00>;
				pinctrl-32 = <0x00>;
				pinctrl-33 = <0x00>;
				pinctrl-34 = <0x00>;
				pinctrl-35 = <0x00>;
				pinctrl-36 = <0x00>;
				pinctrl-37 = <0x00>;
				pinctrl-38 = <0x00>;
				pinctrl-39 = <0x00>;
				pinctrl-40 = <0x00>;
				pinctrl-41 = <0x00>;
				pinctrl-42 = <0x00>;
				pinctrl-43 = <0x00>;
				pinctrl-44 = <0x00>;
				pinctrl-45 = <0x00>;
				pinctrl-46 = <0x00>;
				pinctrl-47 = <0x00>;
				pinctrl-48 = <0x00>;
				pinctrl-49 = <0x00>;
				pinctrl-50 = <0x00>;
				pinctrl-51 = <0x00>;
			};
		};

		fragment@5 {

			__overlay__ {

				camera_main {
					thermal-sensors = <0x00>;
				};

				camera_sub {
					thermal-sensors = <0x00>;
				};

				camera_main_two {
					thermal-sensors = <0x00>;
				};
			};
		};

		fragment@6 {

			__overlay__ {

				lm3643@63 {

					flash@0 {

						port@0 {

							endpoint {
								remote-endpoint = <0x00>;
							};
						};
					};

					flash@1 {

						port@1 {

							endpoint {
								remote-endpoint = <0x00>;
							};
						};
					};
				};
			};
		};

		fragment@7 {

			__overlay__ {

				port@0 {

					endpoint {
						remote-endpoint = <0x00>;
					};
				};

				port@1 {

					endpoint {
						remote-endpoint = <0x00>;
					};
				};
			};
		};

		fragment@10 {

			__overlay__ {
				pinctrl-0 = <0x00>;
				pinctrl-1 = <0x00>;
				pinctrl-2 = <0x00>;
				pinctrl-3 = <0x00>;
			};
		};

		fragment {

			__overlay__ {

				lcds {

					cust_lk_panel {

						display-timings {
							native-mode = <0x00>;
						};
					};

					m100t_ft8201_xy2210d4001a_wuxga2000_pt2 {

						display-timings {
							native-mode = <0x00>;
						};
					};

					m100t_jd9366tc_sq110aq7ez51394l501_wuxga2000_jst_864 {

						display-timings {
							native-mode = <0x00>;
						};
					};
				};
			};
		};

		fragment@16 {

			__overlay__ {
				pinctrl-0 = <0x00>;
				pinctrl-1 = <0x00>;
				pinctrl-2 = <0x00>;
				pinctrl-3 = <0x00>;
				pinctrl-4 = <0x00>;
				pinctrl-5 = <0x00>;
				pinctrl-6 = <0x00>;
				pinctrl-7 = <0x00>;
				pinctrl-8 = <0x00>;
				pinctrl-9 = <0x00>;
				pinctrl-10 = <0x00>;
				pinctrl-11 = <0x00>;
			};
		};

		fragment@17 {

			__overlay__ {
				pinctrl-0 = <0x00>;
				pinctrl-1 = <0x00>;
				pinctrl-2 = <0x00>;
			};
		};

		fragment@18 {

			__overlay__ {

				panel1@0 {

					port {

						endpoint {
							remote-endpoint = <0x00>;
						};
					};
				};

				ports {

					port {

						endpoint {
							remote-endpoint = <0x00>;
						};
					};
				};
			};
		};

		fragment@21 {

			__overlay__ {
				pinctrl-0 = <0x00>;
			};
		};

		fragment@24 {

			__overlay__ {
				pinctrl-0 = <0x00>;
				pinctrl-1 = <0x00>;
				pinctrl-2 = <0x00>;
				pinctrl-3 = <0x00>;
				pinctrl-4 = <0x00>;
				pinctrl-5 = <0x00>;
				pinctrl-6 = <0x00>;
			};
		};

		fragment@38 {

			__overlay__ {
				pinctrl-0 = <0x00>;
				pinctrl-1 = <0x00>;
				pinctrl-2 = <0x00>;
			};
		};

		fragment@40 {

			__overlay__ {

				aw35615@22 {
					pinctrl-0 = <0x00>;
				};
			};
		};

		fragment@42 {

			__overlay__ {
				pinctrl-0 = <0x00>;

				himax@0 {
					pinctrl-0 = <0x00>;
					pinctrl-1 = <0x00>;
				};
			};
		};
	};
};
